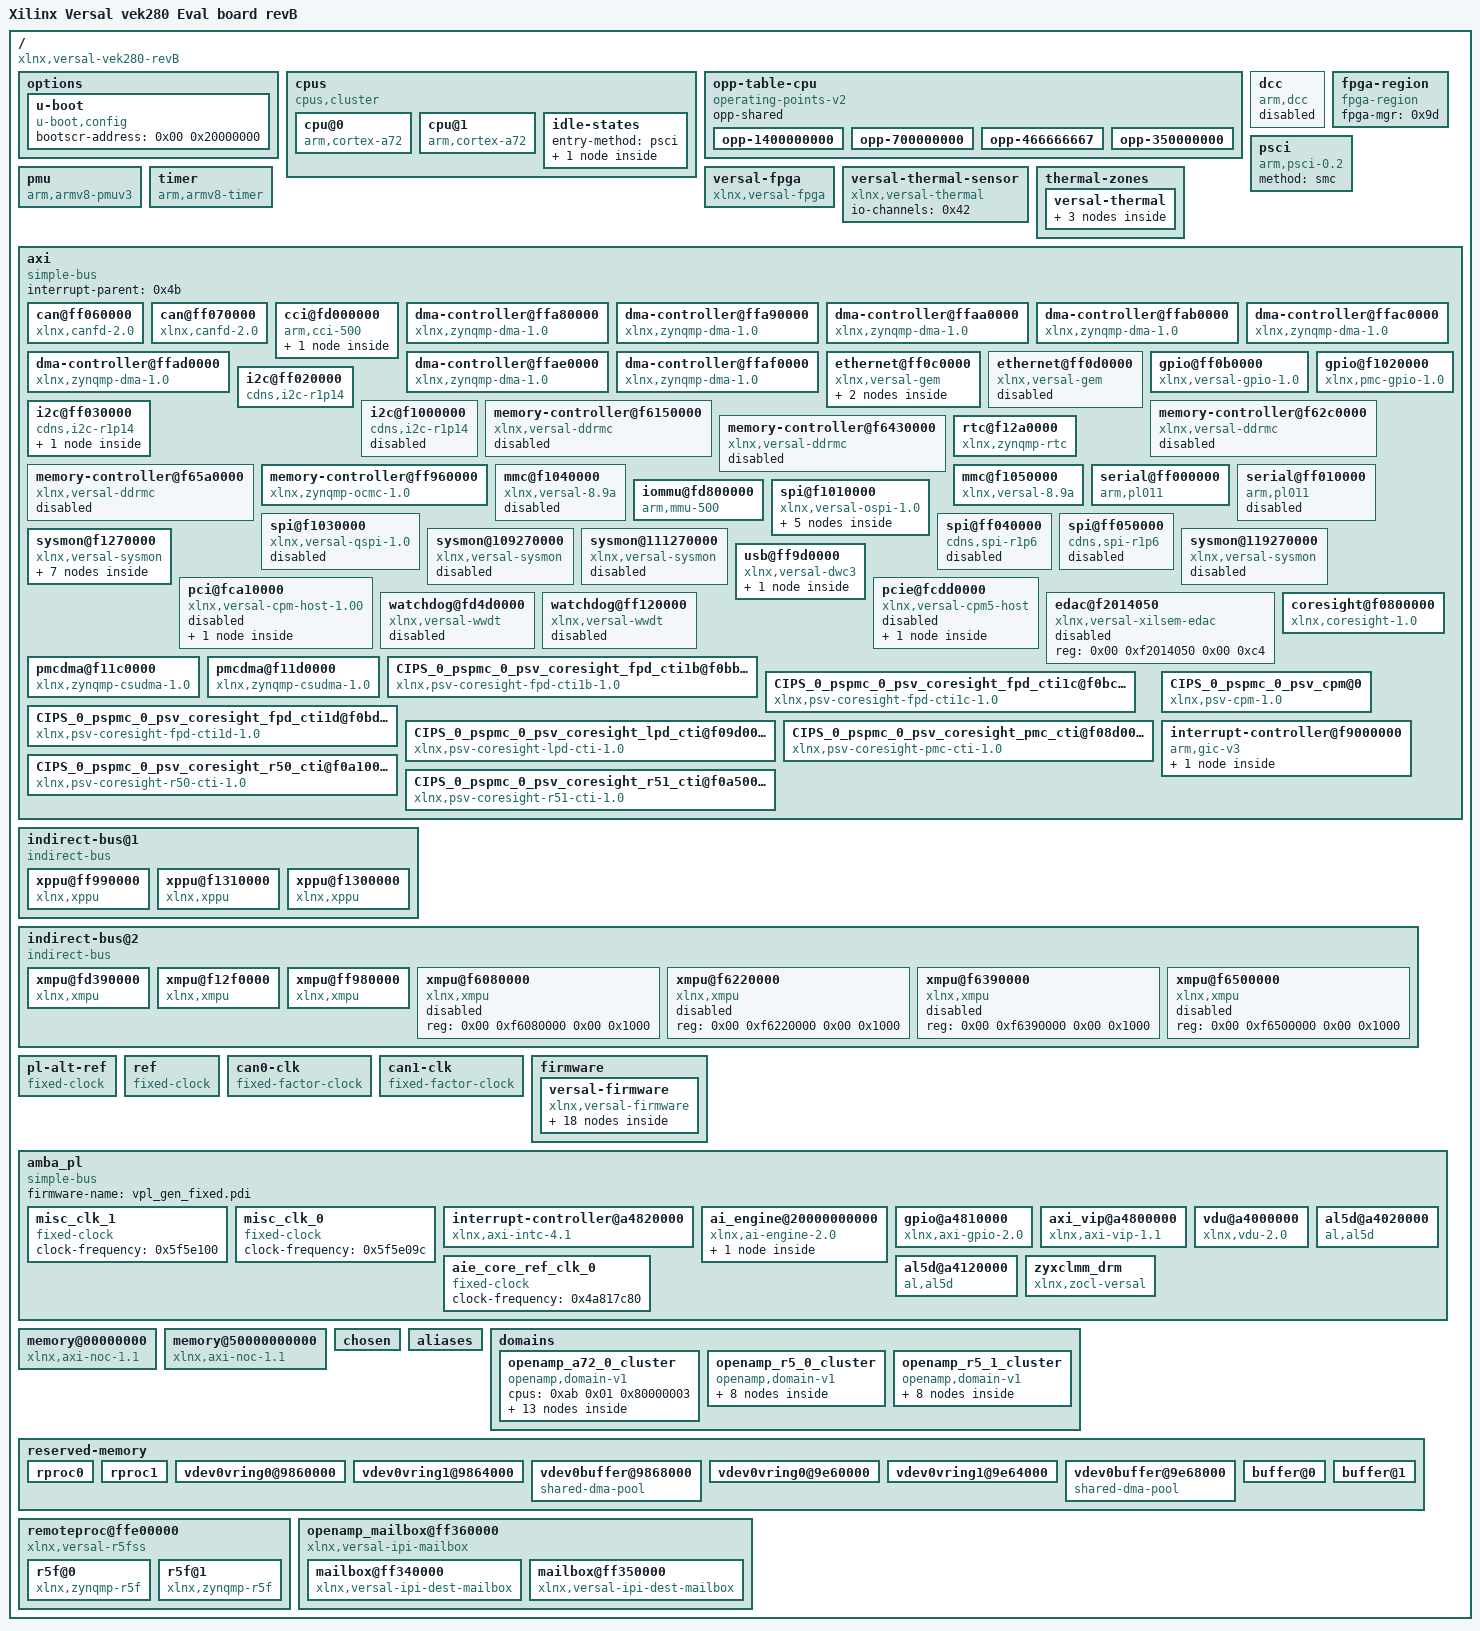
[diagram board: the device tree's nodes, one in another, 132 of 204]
/dts-v1/;

/ {
	compatible = "xlnx,versal-vek280-revB\0xlnx,versal-vek280\0xlnx,versal\0Xilinx Versal vek280 Eval board revB\0Xilinx Versal vek280 Eval board revB\0Xilinx Versal vek280 Eval board revB\0Xilinx Versal vek280 Eval board revB\0Xilinx Versal vek280 Eval board revB\0Xilinx Versal vek280 Eval board revB\0Xilinx Versal vek280 Eval board revB\0Xilinx Versal vek280 Eval board revB\0Xilinx Versal vek280 Eval board revB";
	#address-cells = <0x02>;
	#size-cells = <0x02>;
	model = "Xilinx Versal vek280 Eval board revB";
	board = "vek280";
	device_id = "xcve2802";
	slrcount = <0x01>;
	family = "Versal";
	speed_grade = "2MP";

	options {

		u-boot {
			compatible = "u-boot,config";
			bootscr-address = <0x00 0x20000000>;
		};
	};

	cpus {
		#address-cells = <0x01>;
		#size-cells = <0x00>;
		compatible = "cpus,cluster";
		#ranges-address-cells = <0x02>;
		#ranges-size-cells = <0x02>;
		phandle = <0xab>;

		cpu@0 {
			compatible = "arm,cortex-a72\0arm,armv8";
			device_type = "cpu";
			enable-method = "psci";
			operating-points-v2 = <0x7f>;
			reg = <0x00>;
			cpu-idle-states = <0x80>;
			power-domains = <0x81 0x18110003>;
			clocks = <0x82 0x4d>;
			xlnx,timestamp-clk-freq = <0x5f5e0a4>;
			xlnx,pss-ref-clk-freq = <0x1fca034>;
			stamp-frequency = <0x5f5e0a4>;
			xlnx,ip-name = "psv_cortexa72";
			xlnx,cpu-clk-freq-hz = <0x537248c1>;
			cpu-frequency = <0x537248c1>;
			bus-handle = <0x01>;
			phandle = <0xac>;
		};

		cpu@1 {
			compatible = "arm,cortex-a72\0arm,armv8";
			device_type = "cpu";
			enable-method = "psci";
			operating-points-v2 = <0x7f>;
			reg = <0x01>;
			cpu-idle-states = <0x80>;
			power-domains = <0x81 0x18110004>;
			xlnx,timestamp-clk-freq = <0x5f5e0a4>;
			xlnx,pss-ref-clk-freq = <0x1fca034>;
			stamp-frequency = <0x5f5e0a4>;
			xlnx,ip-name = "psv_cortexa72";
			xlnx,cpu-clk-freq-hz = <0x537248c1>;
			cpu-frequency = <0x537248c1>;
			bus-handle = <0x01>;
			phandle = <0xad>;
		};

		idle-states {
			entry-method = "psci";

			cpu-sleep-0 {
				compatible = "arm,idle-state";
				arm,psci-suspend-param = <0x40000000>;
				local-timer-stop;
				entry-latency-us = <0x12c>;
				exit-latency-us = <0x258>;
				min-residency-us = <0x2710>;
				phandle = <0x80>;
			};
		};
	};

	opp-table-cpu {
		compatible = "operating-points-v2";
		opp-shared;
		phandle = <0x7f>;

		opp-1400000000 {
			opp-hz = <0x00 0x53724e00>;
			clock-latency-ns = <0x7a120>;
			opp-microvolt = <0xf4240>;
		};

		opp-700000000 {
			opp-hz = <0x00 0x29b92700>;
			clock-latency-ns = <0x7a120>;
			opp-microvolt = <0xf4240>;
		};

		opp-466666667 {
			opp-hz = <0x00 0x1bd0c4ab>;
			clock-latency-ns = <0x7a120>;
			opp-microvolt = <0xf4240>;
		};

		opp-350000000 {
			opp-hz = <0x00 0x14dc9380>;
			clock-latency-ns = <0x7a120>;
			opp-microvolt = <0xf4240>;
		};
	};

	dcc {
		compatible = "arm,dcc";
		status = "disabled";
		bootph-all;
		phandle = <0xb6>;
	};

	fpga-region {
		compatible = "fpga-region";
		fpga-mgr = <0x9d>;
		#address-cells = <0x02>;
		#size-cells = <0x02>;
		phandle = <0xb7>;
	};

	psci {
		compatible = "arm,psci-0.2";
		method = "smc";
		phandle = <0xb8>;
	};

	pmu {
		compatible = "arm,armv8-pmuv3";
		interrupt-parent = <0x4b>;
		interrupts = <0x01 0x07 0x304>;
	};

	timer {
		compatible = "arm,armv8-timer";
		interrupt-parent = <0x4b>;
		interrupts = <0x01 0x0d 0x04 0x01 0x0e 0x04 0x01 0x0b 0x04 0x01 0x0a 0x04>;
		phandle = <0xb9>;
	};

	versal-fpga {
		compatible = "xlnx,versal-fpga";
		phandle = <0x9d>;
	};

	versal-thermal-sensor {
		compatible = "xlnx,versal-thermal";
		#thermal-sensor-cells = <0x00>;
		io-channels = <0x42>;
		io-channel-names = "sysmon-temp-channel";
		phandle = <0x9f>;
	};

	thermal-zones {

		versal-thermal {
			polling-delay-passive = <0xfa>;
			polling-delay = <0x3e8>;
			thermal-sensors = <0x9f>;
			phandle = <0xba>;

			trips {

				temp-alert {
					temperature = <0x11170>;
					hysteresis = <0x00>;
					type = "passive";
					phandle = <0xbb>;
				};

				ot-crit {
					temperature = <0x1e848>;
					hysteresis = <0x00>;
					type = "critical";
					phandle = <0xbc>;
				};
			};
		};
	};

	axi {
		compatible = "simple-bus";
		#address-cells = <0x02>;
		#size-cells = <0x02>;
		ranges;
		interrupt-parent = <0x4b>;
		bootph-all;
		phandle = <0x01>;

		can@ff060000 {
			compatible = "xlnx,canfd-2.0";
			status = "okay";
			reg = <0x00 0xff060000 0x00 0x6000>;
			interrupts = <0x00 0x14 0x04>;
			interrupt-parent = <0x4b>;
			clock-names = "can_clk\0s_axi_aclk";
			rx-fifo-depth = <0x40>;
			tx-mailbox-count = <0x20>;
			clocks = <0xa0 0x82 0x52>;
			power-domains = <0x81 0x1822401f>;
			xlnx,can-rx-dpth = <0x40>;
			xlnx,num-of-rx-mb-buf = <0x30>;
			xlnx,can-clk-freq-hz = <0x9896767>;
			xlnx,ip-name = "psv_canfd";
			xlnx,rx-mode = <0x00>;
			xlnx,can-tx-dpth = <0x20>;
			xlnx,num-of-tx-buf = <0x20>;
			xlnx,can-board-interface = "custom";
			phandle = <0x5d>;
		};

		can@ff070000 {
			compatible = "xlnx,canfd-2.0";
			status = "okay";
			reg = <0x00 0xff070000 0x00 0x6000>;
			interrupts = <0x00 0x15 0x04>;
			interrupt-parent = <0x4b>;
			clock-names = "can_clk\0s_axi_aclk";
			rx-fifo-depth = <0x40>;
			tx-mailbox-count = <0x20>;
			clocks = <0xa1 0x82 0x52>;
			power-domains = <0x81 0x18224020>;
			xlnx,can-rx-dpth = <0x40>;
			xlnx,num-of-rx-mb-buf = <0x30>;
			xlnx,can-clk-freq-hz = <0x9896767>;
			xlnx,ip-name = "psv_canfd";
			xlnx,rx-mode = <0x00>;
			xlnx,can-tx-dpth = <0x20>;
			xlnx,num-of-tx-buf = <0x20>;
			xlnx,can-board-interface = "custom";
			phandle = <0x5e>;
		};

		cci@fd000000 {
			compatible = "arm,cci-500";
			status = "okay";
			reg = <0x00 0xfd000000 0x00 0x10000>;
			ranges = <0x00 0x00 0xfd000000 0xa0000>;
			#address-cells = <0x01>;
			#size-cells = <0x01>;
			xlnx,ip-name = "psv_fpd_maincci";
			phandle = <0x4d>;

			pmu@10000 {
				compatible = "arm,cci-500-pmu,r0";
				reg = <0x10000 0x90000>;
				interrupt-parent = <0x4b>;
				interrupts = <0x00 0x6a 0x04 0x00 0x6a 0x04 0x00 0x6a 0x04 0x00 0x6a 0x04 0x00 0x6a 0x04 0x00 0x6a 0x04 0x00 0x6a 0x04 0x00 0x6a 0x04>;
				phandle = <0xbd>;
			};
		};

		dma-controller@ffa80000 {
			compatible = "xlnx,zynqmp-dma-1.0";
			status = "okay";
			reg = <0x00 0xffa80000 0x00 0x1000>;
			interrupts = <0x00 0x3c 0x04>;
			interrupt-parent = <0x4b>;
			clock-names = "clk_main\0clk_apb";
			xlnx,dma-type = <0x01>;
			#dma-cells = <0x01>;
			xlnx,bus-width = <0x40>;
			clocks = <0x82 0x51 0x82 0x52>;
			power-domains = <0x81 0x18224035>;
			xlnx,is-cache-coherent = <0x00>;
			xlnx,ip-name = "psv_adma";
			xlnx,dma-mode = <0x01>;
			phandle = <0x72>;
		};

		dma-controller@ffa90000 {
			compatible = "xlnx,zynqmp-dma-1.0";
			status = "okay";
			reg = <0x00 0xffa90000 0x00 0x1000>;
			interrupts = <0x00 0x3d 0x04>;
			interrupt-parent = <0x4b>;
			clock-names = "clk_main\0clk_apb";
			xlnx,dma-type = <0x01>;
			#dma-cells = <0x01>;
			xlnx,bus-width = <0x40>;
			clocks = <0x82 0x51 0x82 0x52>;
			power-domains = <0x81 0x18224036>;
			xlnx,is-cache-coherent = <0x00>;
			xlnx,ip-name = "psv_adma";
			xlnx,dma-mode = <0x01>;
			phandle = <0x73>;
		};

		dma-controller@ffaa0000 {
			compatible = "xlnx,zynqmp-dma-1.0";
			status = "okay";
			reg = <0x00 0xffaa0000 0x00 0x1000>;
			interrupts = <0x00 0x3e 0x04>;
			interrupt-parent = <0x4b>;
			clock-names = "clk_main\0clk_apb";
			xlnx,dma-type = <0x01>;
			#dma-cells = <0x01>;
			xlnx,bus-width = <0x40>;
			clocks = <0x82 0x51 0x82 0x52>;
			power-domains = <0x81 0x18224037>;
			xlnx,is-cache-coherent = <0x00>;
			xlnx,ip-name = "psv_adma";
			xlnx,dma-mode = <0x01>;
			phandle = <0x74>;
		};

		dma-controller@ffab0000 {
			compatible = "xlnx,zynqmp-dma-1.0";
			status = "okay";
			reg = <0x00 0xffab0000 0x00 0x1000>;
			interrupts = <0x00 0x3f 0x04>;
			interrupt-parent = <0x4b>;
			clock-names = "clk_main\0clk_apb";
			xlnx,dma-type = <0x01>;
			#dma-cells = <0x01>;
			xlnx,bus-width = <0x40>;
			clocks = <0x82 0x51 0x82 0x52>;
			power-domains = <0x81 0x18224038>;
			xlnx,is-cache-coherent = <0x00>;
			xlnx,ip-name = "psv_adma";
			xlnx,dma-mode = <0x01>;
			phandle = <0x75>;
		};

		dma-controller@ffac0000 {
			compatible = "xlnx,zynqmp-dma-1.0";
			status = "okay";
			reg = <0x00 0xffac0000 0x00 0x1000>;
			interrupts = <0x00 0x40 0x04>;
			interrupt-parent = <0x4b>;
			clock-names = "clk_main\0clk_apb";
			xlnx,dma-type = <0x01>;
			#dma-cells = <0x01>;
			xlnx,bus-width = <0x40>;
			clocks = <0x82 0x51 0x82 0x52>;
			power-domains = <0x81 0x18224039>;
			xlnx,is-cache-coherent = <0x00>;
			xlnx,ip-name = "psv_adma";
			xlnx,dma-mode = <0x01>;
			phandle = <0x76>;
		};

		dma-controller@ffad0000 {
			compatible = "xlnx,zynqmp-dma-1.0";
			status = "okay";
			reg = <0x00 0xffad0000 0x00 0x1000>;
			interrupts = <0x00 0x41 0x04>;
			interrupt-parent = <0x4b>;
			clock-names = "clk_main\0clk_apb";
			xlnx,dma-type = <0x01>;
			#dma-cells = <0x01>;
			xlnx,bus-width = <0x40>;
			clocks = <0x82 0x51 0x82 0x52>;
			power-domains = <0x81 0x1822403a>;
			xlnx,is-cache-coherent = <0x00>;
			xlnx,ip-name = "psv_adma";
			xlnx,dma-mode = <0x01>;
			phandle = <0x77>;
		};

		dma-controller@ffae0000 {
			compatible = "xlnx,zynqmp-dma-1.0";
			status = "okay";
			reg = <0x00 0xffae0000 0x00 0x1000>;
			interrupts = <0x00 0x42 0x04>;
			interrupt-parent = <0x4b>;
			clock-names = "clk_main\0clk_apb";
			xlnx,dma-type = <0x01>;
			#dma-cells = <0x01>;
			xlnx,bus-width = <0x40>;
			clocks = <0x82 0x51 0x82 0x52>;
			power-domains = <0x81 0x1822403b>;
			xlnx,is-cache-coherent = <0x00>;
			xlnx,ip-name = "psv_adma";
			xlnx,dma-mode = <0x01>;
			phandle = <0x78>;
		};

		dma-controller@ffaf0000 {
			compatible = "xlnx,zynqmp-dma-1.0";
			status = "okay";
			reg = <0x00 0xffaf0000 0x00 0x1000>;
			interrupts = <0x00 0x43 0x04>;
			interrupt-parent = <0x4b>;
			clock-names = "clk_main\0clk_apb";
			xlnx,dma-type = <0x01>;
			#dma-cells = <0x01>;
			xlnx,bus-width = <0x40>;
			clocks = <0x82 0x51 0x82 0x52>;
			power-domains = <0x81 0x1822403c>;
			xlnx,is-cache-coherent = <0x00>;
			xlnx,ip-name = "psv_adma";
			xlnx,dma-mode = <0x01>;
			phandle = <0x79>;
		};

		ethernet@ff0c0000 {
			compatible = "xlnx,versal-gem\0cdns,gem";
			status = "okay";
			reg = <0x00 0xff0c0000 0x00 0x1000>;
			interrupts = <0x00 0x38 0x04 0x00 0x38 0x04>;
			interrupt-parent = <0x4b>;
			clock-names = "pclk\0hclk\0tx_clk\0rx_clk\0tsu_clk";
			#address-cells = <0x01>;
			#size-cells = <0x00>;
			clocks = <0x82 0x52 0x82 0x58 0x82 0x31 0x82 0x30 0x82 0x2b>;
			power-domains = <0x81 0x18224019>;
			xlnx,has-mdio = <0x01>;
			xlnx,is-cache-coherent = <0x00>;
			xlnx,gem-board-interface = "custom";
			phy-mode = "rgmii-id";
			xlnx,enet-slcr-1000mbps-div0 = <0x02>;
			xlnx,enet-slcr-10mbps-div0 = <0x64>;
			xlnx,enet-tsu-clk-freq-hz = <0xee6b18c>;
			xlnx,ip-name = "psv_ethernet";
			xlnx,eth-mode = <0x01>;
			xlnx,enet-clk-freq-hz = <0x77358c6>;
			xlnx,enet-slcr-100mbps-div0 = <0x0a>;
			phy-handle = <0xa2>;
			phandle = <0x62>;

			mdio {
				#address-cells = <0x01>;
				#size-cells = <0x00>;
				phandle = <0xbe>;

				ethernet-phy@1 {
					#phy-cells = <0x01>;
					compatible = "ethernet-phy-id0283.bc30";
					reg = <0x01>;
					adi,rx-internal-delay-ps = <0x7d0>;
					adi,tx-internal-delay-ps = <0x7d0>;
					adi,fifo-depth-bits = <0x08>;
					reset-gpios = <0x34 0x30 0x01>;
					reset-assert-us = <0x0a>;
					reset-deassert-us = <0x1388>;
					phandle = <0xa2>;
				};
			};
		};

		ethernet@ff0d0000 {
			compatible = "xlnx,versal-gem\0cdns,gem";
			status = "disabled";
			reg = <0x00 0xff0d0000 0x00 0x1000>;
			interrupts = <0x00 0x3a 0x04 0x00 0x3a 0x04>;
			interrupt-parent = <0x4b>;
			clock-names = "pclk\0hclk\0tx_clk\0rx_clk\0tsu_clk";
			#address-cells = <0x01>;
			#size-cells = <0x00>;
			clocks = <0x82 0x52 0x82 0x59 0x82 0x33 0x82 0x32 0x82 0x2b>;
			power-domains = <0x81 0x1822401a>;
			phandle = <0xbf>;
		};

		gpio@ff0b0000 {
			compatible = "xlnx,versal-gpio-1.0";
			status = "okay";
			reg = <0x00 0xff0b0000 0x00 0x1000>;
			interrupts = <0x00 0x0d 0x04>;
			interrupt-parent = <0x4b>;
			#gpio-cells = <0x02>;
			gpio-controller;
			#interrupt-cells = <0x02>;
			interrupt-controller;
			clocks = <0x82 0x52>;
			power-domains = <0x81 0x18224023>;
			xlnx,ip-name = "psv_gpio";
			emio-gpio-width = [00];
			phandle = <0x61>;
		};

		gpio@f1020000 {
			compatible = "xlnx,pmc-gpio-1.0";
			status = "okay";
			reg = <0x00 0xf1020000 0x00 0x1000>;
			interrupts = <0x00 0x7a 0x04>;
			interrupt-parent = <0x4b>;
			#gpio-cells = <0x02>;
			gpio-controller;
			#interrupt-cells = <0x02>;
			interrupt-controller;
			clocks = <0x82 0x3d>;
			power-domains = <0x81 0x1822402c>;
			xlnx,ip-name = "psv_pmc_gpio";
			phandle = <0x34>;
		};

		i2c@ff020000 {
			compatible = "cdns,i2c-r1p14";
			status = "okay";
			reg = <0x00 0xff020000 0x00 0x1000>;
			interrupts = <0x00 0x0e 0x04>;
			interrupt-parent = <0x4b>;
			clock-frequency = <0x186a0>;
			#address-cells = <0x01>;
			#size-cells = <0x00>;
			clocks = <0x82 0x62>;
			power-domains = <0x81 0x1822401d>;
			xlnx,clock-freq = <0x5f5e0a4>;
			xlnx,i2c-clk-freq-hz = <0x5f5e0a4>;
			xlnx,ip-name = "psv_i2c";
			xlnx,iic-board-interface = "custom";
			phandle = <0x5b>;
		};

		i2c@ff030000 {
			compatible = "cdns,i2c-r1p14";
			status = "okay";
			reg = <0x00 0xff030000 0x00 0x1000>;
			interrupts = <0x00 0x0f 0x04>;
			interrupt-parent = <0x4b>;
			clock-frequency = <0x186a0>;
			#address-cells = <0x01>;
			#size-cells = <0x00>;
			clocks = <0x82 0x63>;
			power-domains = <0x81 0x1822401e>;
			xlnx,clock-freq = <0x5f5e0a4>;
			xlnx,i2c-clk-freq-hz = <0x5f5e0a4>;
			xlnx,ip-name = "psv_i2c";
			xlnx,iic-board-interface = "custom";
			bootph-all;
			phandle = <0x5c>;

			eeprom@54 {
				compatible = "st,24c128\0atmel,24c128";
				reg = <0x54>;
				bootph-all;
				phandle = <0xc0>;
			};
		};

		i2c@f1000000 {
			compatible = "cdns,i2c-r1p14";
			status = "disabled";
			reg = <0x00 0xf1000000 0x00 0x1000>;
			interrupts = <0x00 0x7b 0x04>;
			interrupt-parent = <0x4b>;
			clock-frequency = <0x186a0>;
			#address-cells = <0x01>;
			#size-cells = <0x00>;
			clocks = <0x82 0x3e>;
			power-domains = <0x81 0x1822402d>;
			phandle = <0xc1>;
		};

		memory-controller@f6150000 {
			compatible = "xlnx,versal-ddrmc";
			status = "disabled";
			reg = <0x00 0xf6150000 0x00 0x2000 0x00 0xf6070000 0x00 0x20000>;
			reg-names = "base\0noc";
			interrupts = <0x00 0x93 0x04>;
			interrupt-parent = <0x4b>;
			phandle = <0xc2>;
		};

		memory-controller@f62c0000 {
			compatible = "xlnx,versal-ddrmc";
			status = "disabled";
			reg = <0x00 0xf62c0000 0x00 0x2000 0x00 0xf6210000 0x00 0x20000>;
			reg-names = "base\0noc";
			interrupts = <0x00 0x93 0x04>;
			interrupt-parent = <0x4b>;
			phandle = <0xc3>;
		};

		memory-controller@f6430000 {
			compatible = "xlnx,versal-ddrmc";
			status = "disabled";
			reg = <0x00 0xf6430000 0x00 0x2000 0x00 0xf6380000 0x00 0x20000>;
			reg-names = "base\0noc";
			interrupts = <0x00 0x93 0x04>;
			interrupt-parent = <0x4b>;
			phandle = <0xc4>;
		};

		memory-controller@f65a0000 {
			compatible = "xlnx,versal-ddrmc";
			status = "disabled";
			reg = <0x00 0xf65a0000 0x00 0x2000 0x00 0xf64f0000 0x00 0x20000>;
			reg-names = "base\0noc";
			interrupts = <0x00 0x93 0x04>;
			interrupt-parent = <0x4b>;
			phandle = <0xc5>;
		};

		memory-controller@ff960000 {
			compatible = "xlnx,zynqmp-ocmc-1.0";
			reg = <0x00 0xff960000 0x00 0x1000>;
			interrupts = <0x00 0x0a 0x04>;
			interrupt-parent = <0x4b>;
			phandle = <0xc6>;
		};

		rtc@f12a0000 {
			compatible = "xlnx,zynqmp-rtc";
			status = "okay";
			reg = <0x00 0xf12a0000 0x00 0x100>;
			interrupt-names = "alarm\0sec";
			interrupts = <0x00 0x8e 0x04 0x00 0x8f 0x04>;
			interrupt-parent = <0x4b>;
			calibration = <0x7fff>;
			power-domains = <0x81 0x18224034>;
			xlnx,ip-name = "psv_pmc_rtc";
			phandle = <0x43>;
		};

		mmc@f1040000 {
			compatible = "xlnx,versal-8.9a\0arasan,sdhci-8.9a";
			status = "disabled";
			reg = <0x00 0xf1040000 0x00 0x10000>;
			interrupts = <0x00 0x7e 0x04>;
			interrupt-parent = <0x4b>;
			clock-names = "clk_xin\0clk_ahb\0gate";
			#clock-cells = <0x01>;
			clock-output-names = "clk_out_sd0\0clk_in_sd0";
			clocks = <0x82 0x3b 0x82 0x52 0x82 0x4a>;
			power-domains = <0x81 0x1822402e>;
			phandle = <0xc7>;
		};

		mmc@f1050000 {
			compatible = "xlnx,versal-8.9a\0arasan,sdhci-8.9a";
			status = "okay";
			reg = <0x00 0xf1050000 0x00 0x10000>;
			interrupts = <0x00 0x80 0x04>;
			interrupt-parent = <0x4b>;
			clock-names = "clk_xin\0clk_ahb\0gate";
			#clock-cells = <0x01>;
			clock-output-names = "clk_out_sd1\0clk_in_sd1";
			clocks = <0x82 0x3c 0x82 0x52 0x82 0x4a>;
			power-domains = <0x81 0x1822402f>;
			xlnx,sd-board-interface = "custom";
			xlnx,is-cache-coherent = <0x00>;
			xlnx,clk-50-ddr-otap-dly = <0x03>;
			xlnx,clk-50-sdr-itap-dly = <0x2c>;
			xlnx,has-emio = <0x00>;
			clock-frequency = <0xbebc149>;
			xlnx,clk-100-sdr-otap-dly = <0x03>;
			xlnx,mio-bank = <0x01>;
			xlnx,ip-name = "psv_pmc_sd";
			xlnx,bus-width = <0x08>;
			xlnx,card-detect = <0x01>;
			xlnx,has-wp = <0x00>;
			xlnx,has-cd = <0x01>;
			xlnx,slot-type = <0x03>;
			xlnx,clk-50-sdr-otap-dly = <0x04>;
			xlnx,clk-50-ddr-itap-dly = <0x36>;
			xlnx,has-power = <0x01>;
			xlnx,clk-200-sdr-otap-dly = <0x02>;
			xlnx,sdio-clk-freq-hz = <0xbebc149>;
			xlnx,write-protect = <0x00>;
			no-1-8-v;
			phandle = <0x35>;
		};

		serial@ff000000 {
			compatible = "arm,pl011\0arm,primecell";
			status = "okay";
			reg = <0x00 0xff000000 0x00 0x1000>;
			interrupts = <0x00 0x12 0x04>;
			interrupt-parent = <0x4b>;
			reg-io-width = <0x04>;
			clock-names = "uartclk\0apb_pclk";
			bootph-all;
			clocks = <0x82 0x5c 0x82 0x52>;
			power-domains = <0x81 0x18224021>;
			xlnx,clock-freq = <0x5f5e0a4>;
			u-boot,dm-pre-reloc;
			xlnx,uart-board-interface = "custom";
			xlnx,has-modem = <0x00>;
			xlnx,ip-name = "psv_sbsauart";
			xlnx,baudrate = <0x1c200>;
			cts-override;
			port-number = <0x00>;
			xlnx,uart-clk-freq-hz = <0x5f5e0a4>;
			phandle = <0x5a>;
		};

		serial@ff010000 {
			compatible = "arm,pl011\0arm,primecell";
			status = "disabled";
			reg = <0x00 0xff010000 0x00 0x1000>;
			interrupts = <0x00 0x13 0x04>;
			interrupt-parent = <0x4b>;
			reg-io-width = <0x04>;
			clock-names = "uartclk\0apb_pclk";
			bootph-all;
			clocks = <0x82 0x5d 0x82 0x52>;
			power-domains = <0x81 0x18224022>;
			phandle = <0xc8>;
		};

		iommu@fd800000 {
			compatible = "arm,mmu-500";
			status = "okay";
			reg = <0x00 0xfd800000 0x00 0x40000>;
			stream-match-mask = <0x7c00>;
			#iommu-cells = <0x01>;
			#global-interrupts = <0x01>;
			interrupts = <0x00 0x6b 0x04 0x00 0x6b 0x04 0x00 0x6b 0x04 0x00 0x6b 0x04 0x00 0x6b 0x04 0x00 0x6b 0x04 0x00 0x6b 0x04 0x00 0x6b 0x04 0x00 0x6b 0x04 0x00 0x6b 0x04 0x00 0x6b 0x04 0x00 0x6b 0x04 0x00 0x6b 0x04 0x00 0x6b 0x04 0x00 0x6b 0x04 0x00 0x6b 0x04 0x00 0x6b 0x04 0x00 0x6b 0x04 0x00 0x6b 0x04 0x00 0x6b 0x04 0x00 0x6b 0x04 0x00 0x6b 0x04 0x00 0x6b 0x04 0x00 0x6b 0x04 0x00 0x6b 0x04 0x00 0x6b 0x04 0x00 0x6b 0x04 0x00 0x6b 0x04 0x00 0x6b 0x04 0x00 0x6b 0x04 0x00 0x6b 0x04 0x00 0x6b 0x04 0x00 0x6b 0x04>;
			interrupt-parent = <0x4b>;
			xlnx,ip-name = "psv_fpd_smmutcu";
			phandle = <0x58>;
		};

		spi@f1010000 {
			compatible = "xlnx,versal-ospi-1.0\0cdns,qspi-nor";
			status = "okay";
			reg = <0x00 0xf1010000 0x00 0x10000 0x00 0xc0000000 0x00 0x20000000>;
			interrupts = <0x00 0x7c 0x04>;
			interrupt-parent = <0x4b>;
			cdns,fifo-depth = <0x100>;
			cdns,fifo-width = <0x04>;
			cdns,is-dma = <0x01>;
			cdns,trigger-address = <0xc0000000>;
			#address-cells = <0x01>;
			#size-cells = <0x00>;
			clocks = <0x82 0x3a>;
			power-domains = <0x81 0x1822402a>;
			reset-names = "qspi";
			resets = <0xa3 0xc10402e>;
			is-stacked = <0x00>;
			xlnx,is-cache-coherent = <0x00>;
			xlnx,clock-freq = <0xbebc149>;
			xlnx,ip-name = "psv_pmc_ospi";
			xlnx,ospi-clk-freq-hz = <0xbebc149>;
			is-dual = <0x00>;
			xlnx,ospi-mode = <0x00>;
			bus-num = <0x02>;
			num-cs = <0x01>;
			#stream-id-cells = <0x01>;
			phandle = <0x33>;

			flash@0 {
				compatible = "mt35xu02g\0micron,m25p80\0jedec,spi-nor";
				reg = <0x00>;
				#address-cells = <0x01>;
				#size-cells = <0x01>;
				cdns,read-delay = <0x00>;
				cdns,tshsl-ns = <0x00>;
				cdns,tsd2d-ns = <0x00>;
				cdns,tchsh-ns = <0x01>;
				cdns,tslch-ns = <0x01>;
				spi-tx-bus-width = <0x08>;
				spi-rx-bus-width = <0x08>;
				spi-max-frequency = <0x1312d00>;
				no-wp;
				reset-gpios = <0x34 0x0c 0x01>;
				phandle = <0x02>;

				partition@0 {
					label = "spi0-boot";
					reg = <0x00 0x40000>;
				};

				partition@1 {
					label = "spi0-bootenv";
					reg = <0x40000 0x20000>;
				};

				partition@2 {
					label = "spi0-config";
					reg = <0x60000 0x20000>;
				};

				partition@3 {
					label = "spi0-kernel";
					reg = <0x80000 0xc00000>;
				};
			};
		};

		spi@f1030000 {
			compatible = "xlnx,versal-qspi-1.0";
			status = "disabled";
			reg = <0x00 0xf1030000 0x00 0x1000>;
			interrupts = <0x00 0x7d 0x04>;
			interrupt-parent = <0x4b>;
			clock-names = "ref_clk\0pclk";
			#address-cells = <0x01>;
			#size-cells = <0x00>;
			clocks = <0x82 0x39 0x82 0x52>;
			power-domains = <0x81 0x1822402b>;
			phandle = <0xc9>;
		};

		spi@ff040000 {
			compatible = "cdns,spi-r1p6";
			status = "disabled";
			reg = <0x00 0xff040000 0x00 0x1000>;
			interrupts = <0x00 0x10 0x04>;
			interrupt-parent = <0x4b>;
			clock-names = "ref_clk\0pclk";
			#address-cells = <0x01>;
			#size-cells = <0x00>;
			clocks = <0x82 0x5e 0x82 0x52>;
			power-domains = <0x81 0x1822401b>;
			phandle = <0xca>;
		};

		spi@ff050000 {
			compatible = "cdns,spi-r1p6";
			status = "disabled";
			reg = <0x00 0xff050000 0x00 0x1000>;
			interrupts = <0x00 0x11 0x04>;
			interrupt-parent = <0x4b>;
			clock-names = "ref_clk\0pclk";
			#address-cells = <0x01>;
			#size-cells = <0x00>;
			clocks = <0x82 0x5f 0x82 0x52>;
			power-domains = <0x81 0x1822401c>;
			phandle = <0xcb>;
		};

		sysmon@f1270000 {
			compatible = "xlnx,versal-sysmon";
			#io-channel-cells = <0x00>;
			reg = <0x00 0xf1270000 0x00 0x4000>;
			interrupts = <0x00 0x90 0x04>;
			xlnx,numchannels = [07];
			#address-cells = <0x02>;
			#size-cells = <0x02>;
			xlnx,nodeid = <0x18224055>;
			xlnx,sat-63-desc = "PS , FPD , satellite";
			xlnx,sat-1-desc = "PMC , system , ADC";
			xlnx,sat-17-x = <0x40b7>;
			xlnx,sat-9-x = <0x315e>;
			xlnx,sat-20-desc = "VNOC , satellite";
			xlnx,sat-19-desc = "Clocking , column , satellite";
			xlnx,sat-17-y = <0x1795>;
			xlnx,sat-9-y = <0x34f8>;
			xlnx,sat-22-x = <0x2624>;
			xlnx,meas-0-root-id = <0x00>;
			xlnx,sat-22-y = <0x25ed>;
			xlnx,meas-1-root-id = <0x05>;
			xlnx,ip-name = "psv_pmc_sysmon";
			xlnx,meas-2-root-id = <0x01>;
			xlnx,sat-16-desc = "Clocking , column , satellite";
			xlnx,meas-2-slr-number = <0x00>;
			xlnx,meas-3-root-id = <0x02>;
			xlnx,sat-9-desc = "ME , satellite";
			xlnx,sat-26-x = <0x18d1>;
			xlnx,meas-4-root-id = <0x03>;
			xlnx,sat-28-desc = "ME , satellite";
			xlnx,sat-26-y = <0x19f9>;
			xlnx,meas-5-root-id = <0x04>;
			xlnx,sat-10-x = <0x2995>;
			xlnx,sat-64-x = <0x23>;
			xlnx,sat-2-x = <0x23>;
			xlnx,meas-6-root-id = <0x06>;
			xlnx,sat-10-y = <0x34f8>;
			xlnx,sat-64-y = <0xb34>;
			xlnx,sat-2-y = <0xb34>;
			xlnx,sat-13-desc = "Clocking , column , satellite";
			xlnx,sat-31-x = <0xa0e>;
			xlnx,sat-6-desc = "VNOC , satellite";
			xlnx,sat-31-y = <0x2ff0>;
			xlnx,sat-14-x = <0x40b7>;
			xlnx,sat-6-x = <0x3377>;
			xlnx,sat-25-desc = "VNOC , satellite";
			xlnx,sat-14-y = <0x29b7>;
			xlnx,sat-6-y = <0xe06>;
			xlnx,sat-10-desc = "ME , satellite";
			xlnx,sat-18-x = <0x40b7>;
			xlnx,sat-3-desc = "XPIO , satellite";
			xlnx,sat-18-y = <0x11d0>;
			xlnx,meas-5-slr-number = <0x00>;
			xlnx,sat-22-desc = "VNOC , satellite";
			xlnx,sat-23-x = <0x21cc>;
			xlnx,meas-0-slr-number = <0x00>;
			xlnx,sat-23-y = <0x34f8>;
			xlnx,sat-18-desc = "Clocking , column , satellite";
			xlnx,sat-27-x = <0x18d1>;
			xlnx,sat-27-y = <0x25ed>;
			xlnx,sat-11-x = <0x3926>;
			xlnx,sat-3-x = <0x116a>;
			xlnx,sat-31-desc = "Clocking , column , satellite";
			xlnx,sat-11-y = <0x34f8>;
			xlnx,sat-3-y = <0x5ff>;
			status = "okay";
			xlnx,sat-15-desc = "Clocking , column , satellite";
			xlnx,sat-15-x = <0x40b7>;
			xlnx,sat-8-desc = "VNOC , satellite";
			xlnx,sat-7-x = <0x3377>;
			xlnx,sat-15-y = <0x2389>;
			xlnx,sat-7-y = <0x19f9>;
			xlnx,sat-27-desc = "VNOC , satellite";
			xlnx,meas-3-slr-number = <0x00>;
			xlnx,sat-20-x = <0x2624>;
			xlnx,sat-19-x = <0x40b7>;
			xlnx,sat-12-desc = "ME , satellite";
			xlnx,sat-20-y = <0xe06>;
			xlnx,sat-19-y = <0xba1>;
			xlnx,sat-5-desc = "XPIO , satellite";
			xlnx,sat-24-desc = "ME , satellite";
			xlnx,sat-24-x = <0x1a03>;
			xlnx,sat-24-y = <0x34f8>;
			xlnx,sat-64-desc = "PS , LPD , satellite";
			xlnx,sat-2-desc = "PMC , user , ADC";
			xlnx,sat-28-x = <0x123a>;
			xlnx,sat-21-desc = "VNOC , satellite";
			xlnx,sat-28-y = <0x34f8>;
			xlnx,meas-6-slr-number = <0x00>;
			xlnx,sat-12-x = <0x40ef>;
			xlnx,sat-4-x = <0x290a>;
			xlnx,sat-12-y = <0x34f8>;
			xlnx,sat-4-y = <0x5ff>;
			xlnx,meas-1-slr-number = <0x00>;
			xlnx,sat-16-x = <0x40b7>;
			xlnx,sat-17-desc = "Clocking , column , satellite";
			xlnx,sat-8-x = <0x3377>;
			xlnx,sat-16-y = <0x1dc4>;
			xlnx,sat-8-y = <0x25ed>;
			xlnx,meas-0 = "VCCAUX";
			xlnx,sat-30-desc = "ME , satellite";
			xlnx,sat-29-desc = "ME , satellite";
			xlnx,meas-1 = "VCC_SOC";
			xlnx,sat-21-x = <0x2624>;
			xlnx,meas-2 = "VCCAUX_PMC";
			xlnx,sat-21-y = <0x19f9>;
			xlnx,meas-3 = "VCC_PMC";
			xlnx,sat-14-desc = "Clocking , column , satellite";
			xlnx,meas-4 = "VCC_PSFP";
			xlnx,sat-7-desc = "VNOC , satellite";
			xlnx,meas-5 = "VCC_PSLP";
			xlnx,sat-26-desc = "VNOC , satellite";
			xlnx,sat-25-x = <0x18d1>;
			xlnx,meas-6 = "VP_VN";
			xlnx,sat-25-y = <0xe06>;
			xlnx,sat-63-x = <0x23>;
			xlnx,sat-1-x = <0x23>;
			xlnx,meas-4-slr-number = <0x00>;
			xlnx,sat-11-desc = "ME , satellite";
			xlnx,sat-63-y = <0xb34>;
			xlnx,sat-1-y = <0xb34>;
			xlnx,sat-4-desc = "XPIO , satellite";
			xlnx,sat-30-x = <0x2a8>;
			xlnx,sat-29-x = <0xa71>;
			xlnx,sat-30-y = <0x34f8>;
			xlnx,sat-29-y = <0x34f8>;
			xlnx,sat-23-desc = "ME , satellite";
			xlnx,sat-13-x = <0x40b7>;
			xlnx,sat-5-x = <0x40aa>;
			xlnx,sat-13-y = <0x2ff0>;
			xlnx,sat-5-y = <0x5ff>;
			phandle = <0x42>;

			supply@0 {
				reg = <0x00>;
				xlnx,name = "vccaux";
			};

			supply@5 {
				reg = <0x05>;
				xlnx,name = "vcc_soc";
			};

			supply@1 {
				reg = <0x01>;
				xlnx,name = "vccaux_pmc";
			};

			supply@2 {
				reg = <0x02>;
				xlnx,name = "vcc_pmc";
			};

			supply@3 {
				reg = <0x03>;
				xlnx,name = "vcc_psfp";
			};

			supply@4 {
				reg = <0x04>;
				xlnx,name = "vcc_pslp";
			};

			supply@6 {
				reg = <0x06>;
				xlnx,name = "vp_vn";
			};
		};

		sysmon@109270000 {
			compatible = "xlnx,versal-sysmon";
			status = "disabled";
			reg = <0x01 0x9270000 0x00 0x4000>;
			xlnx,numchannels = [00];
			#address-cells = <0x01>;
			#size-cells = <0x00>;
			xlnx,nodeid = <0x18225055>;
			phandle = <0xcc>;
		};

		sysmon@111270000 {
			compatible = "xlnx,versal-sysmon";
			status = "disabled";
			reg = <0x01 0x11270000 0x00 0x4000>;
			xlnx,numchannels = [00];
			#address-cells = <0x01>;
			#size-cells = <0x00>;
			xlnx,nodeid = <0x18226055>;
			phandle = <0xcd>;
		};

		sysmon@119270000 {
			compatible = "xlnx,versal-sysmon";
			status = "disabled";
			reg = <0x01 0x19270000 0x00 0x4000>;
			xlnx,numchannels = [00];
			#address-cells = <0x01>;
			#size-cells = <0x00>;
			xlnx,nodeid = <0x18227055>;
			phandle = <0xce>;
		};

		usb@ff9d0000 {
			compatible = "xlnx,versal-dwc3";
			status = "okay";
			reg = <0x00 0xff9d0000 0x00 0x100>;
			clock-names = "bus_clk\0ref_clk";
			ranges;
			#address-cells = <0x02>;
			#size-cells = <0x02>;
			clocks = <0x82 0x5b 0x82 0x68>;
			power-domains = <0x81 0x18224018>;
			resets = <0xa3 0xc104036>;
			xlnx,ip-name = "psv_usb";
			phandle = <0x71>;

			usb@fe200000 {
				compatible = "snps,dwc3";
				status = "okay";
				reg = <0x00 0xfe200000 0x00 0x10000>;
				interrupt-names = "host\0peripheral\0otg\0wakeup";
				interrupts = <0x00 0x16 0x04 0x00 0x16 0x04 0x00 0x1a 0x04 0x00 0x4a 0x04>;
				interrupt-parent = <0x4b>;
				snps,dis_u2_susphy_quirk;
				snps,dis_u3_susphy_quirk;
				snps,quirk-frame-length-adjustment = <0x20>;
				clock-names = "ref";
				clocks = <0x82 0x5b>;
				xlnx,is-cache-coherent = <0x00>;
				xlnx,ip-name = "psv_usb_xhci";
				xlnx,enable-superspeed = <0x00>;
				dr_mode = "host";
				maximum-speed = "high-speed";
				snps,usb3_lpm_capable;
				phandle = <0x59>;
			};
		};

		pci@fca10000 {
			device_type = "pci";
			#address-cells = <0x03>;
			#interrupt-cells = <0x01>;
			#size-cells = <0x02>;
			compatible = "xlnx,versal-cpm-host-1.00";
			status = "disabled";
			interrupt-map = <0x01 0xa4 0x00 0x02 0xa4 0x01 0x03 0xa4 0x02 0x04 0xa4 0x03>;
			interrupt-map-mask = <0x00 0x00 0x00 0x07>;
			interrupt-names = "misc";
			interrupts = <0x00 0x48 0x04>;
			xlnx,csr-slcr = <0x06 0x00>;
			xlnx,num-of-bars = <0x02>;
			xlnx,port-type = <0x01>;
			interrupt-parent = <0x4b>;
			bus-range = <0x00 0xff>;
			ranges = <0x2000000 0x00 0xe0010000 0x00 0xe0010000 0x00 0x10000000 0x43000000 0x80 0x00 0x80 0x00 0x00 0x80000000>;
			msi-map = <0x00 0x07 0x00 0x10000>;
			reg = <0x06 0x00 0x00 0x1000000 0x00 0xfca10000 0x00 0x1000 0x00 0xfca00000 0x00 0x10000>;
			reg-names = "cfg\0cpm_slcr\0cpm_crx";
			phandle = <0xcf>;

			interrupt-controller {
				#address-cells = <0x00>;
				#interrupt-cells = <0x01>;
				interrupt-controller;
				phandle = <0xa4>;
			};
		};

		pcie@fcdd0000 {
			device_type = "pci";
			#address-cells = <0x03>;
			#interrupt-cells = <0x01>;
			#size-cells = <0x02>;
			compatible = "xlnx,versal-cpm5-host";
			status = "disabled";
			interrupt-map = <0x01 0xa5 0x00 0x02 0xa5 0x01 0x03 0xa5 0x02 0x04 0xa5 0x03>;
			interrupt-map-mask = <0x00 0x00 0x00 0x07>;
			interrupt-names = "misc";
			interrupts = <0x00 0x48 0x04>;
			xlnx,csr-slcr = <0xfce20000>;
			xlnx,num-of-bars = <0x02>;
			xlnx,port-type = <0x01>;
			interrupt-parent = <0x4b>;
			bus-range = <0x00 0xff>;
			ranges = <0x2000000 0x00 0xe0000000 0x00 0xe0000000 0x00 0x10000000 0x43000000 0x80 0x00 0x80 0x00 0x00 0x80000000>;
			msi-map = <0x00 0x07 0x00 0x10000>;
			reg = <0x06 0x00 0x00 0x1000000 0x00 0xfcdd0000 0x00 0x1000 0x00 0xfce20000 0x00 0x10000 0x00 0xfcdc0000 0x00 0x10000>;
			reg-names = "cfg\0cpm_slcr\0cpm_csr\0cpm_crx";
			phandle = <0xd0>;

			interrupt-controller {
				#address-cells = <0x00>;
				#interrupt-cells = <0x01>;
				interrupt-controller;
				phandle = <0xa5>;
			};
		};

		watchdog@fd4d0000 {
			compatible = "xlnx,versal-wwdt";
			status = "disabled";
			reg = <0x00 0xfd4d0000 0x00 0x10000>;
			interrupt-names = "wdt\0wwdt_reset_pending\0gwdt\0gwdt_reset_pending";
			interrupts = <0x00 0x64 0x01 0x00 0x6d 0x01 0x00 0x6c 0x01 0x00 0x6e 0x01>;
			interrupt-parent = <0x4b>;
			timeout-sec = <0x1e>;
			clocks = <0x82 0x4c>;
			power-domains = <0x81 0x18224029>;
			phandle = <0xd1>;
		};

		watchdog@ff120000 {
			compatible = "xlnx,versal-wwdt";
			status = "disabled";
			reg = <0x00 0xff120000 0x00 0x10000>;
			interrupt-parent = <0x4b>;
			interrupt-names = "wdt\0wwdt_reset_pending\0gwdt\0gwdt_reset_pending";
			interrupts = <0x00 0x31 0x01 0x00 0x45 0x01 0x00 0x46 0x04 0x00 0x47 0x04>;
			timeout-sec = <0x1e>;
			clocks = <0x82 0x52>;
			power-domains = <0x81 0x18224028>;
			phandle = <0xd2>;
		};

		edac@f2014050 {
			compatible = "xlnx,versal-xilsem-edac";
			status = "disabled";
			reg = <0x00 0xf2014050 0x00 0xc4>;
			phandle = <0xd3>;
		};

		pmcdma@f11c0000 {
			status = "okay";
			compatible = "xlnx,zynqmp-csudma-1.0";
			interrupt-parent = <0x4b>;
			interrupts = <0x00 0x83 0x04>;
			reg = <0x00 0xf11c0000 0x00 0x10000>;
			xlnx,dma-type = <0x01>;
			xlnx,ip-name = "psv_pmc_dma";
			phandle = <0x37>;
		};

		pmcdma@f11d0000 {
			status = "okay";
			compatible = "xlnx,zynqmp-csudma-1.0";
			interrupt-parent = <0x4b>;
			interrupts = <0x00 0x84 0x04>;
			reg = <0x00 0xf11d0000 0x00 0x10000>;
			xlnx,dma-type = <0x02>;
			xlnx,ip-name = "psv_pmc_dma";
			phandle = <0x38>;
		};

		coresight@f0800000 {
			compatible = "xlnx,coresight-1.0";
			status = "okay";
			reg = <0x00 0xf0800000 0x00 0x10000>;
			xlnx,ip-name = "psv_coresight";
			phandle = <0x13>;
		};

		CIPS_0_pspmc_0_psv_coresight_fpd_cti1b@f0bb0000 {
			compatible = "xlnx,psv-coresight-fpd-cti1b-1.0";
			status = "okay";
			xlnx,ip-name = "psv_coresight_fpd_cti1b";
			reg = <0x00 0xf0bb0000 0x00 0x10000>;
			phandle = <0x1b>;
		};

		CIPS_0_pspmc_0_psv_coresight_fpd_cti1c@f0bc0000 {
			compatible = "xlnx,psv-coresight-fpd-cti1c-1.0";
			status = "okay";
			xlnx,ip-name = "psv_coresight_fpd_cti1c";
			reg = <0x00 0xf0bc0000 0x00 0x10000>;
			phandle = <0x1c>;
		};

		CIPS_0_pspmc_0_psv_coresight_fpd_cti1d@f0bd0000 {
			compatible = "xlnx,psv-coresight-fpd-cti1d-1.0";
			status = "okay";
			xlnx,ip-name = "psv_coresight_fpd_cti1d";
			reg = <0x00 0xf0bd0000 0x00 0x10000>;
			phandle = <0x1d>;
		};

		CIPS_0_pspmc_0_psv_coresight_lpd_cti@f09d0000 {
			compatible = "xlnx,psv-coresight-lpd-cti-1.0";
			status = "okay";
			xlnx,ip-name = "psv_coresight_lpd_cti";
			reg = <0x00 0xf09d0000 0x00 0x10000>;
			phandle = <0x16>;
		};

		CIPS_0_pspmc_0_psv_coresight_pmc_cti@f08d0000 {
			compatible = "xlnx,psv-coresight-pmc-cti-1.0";
			status = "okay";
			xlnx,ip-name = "psv_coresight_pmc_cti";
			reg = <0x00 0xf08d0000 0x00 0x10000>;
			phandle = <0x14>;
		};

		CIPS_0_pspmc_0_psv_coresight_r50_cti@f0a10000 {
			compatible = "xlnx,psv-coresight-r50-cti-1.0";
			status = "okay";
			xlnx,ip-name = "psv_coresight_r50_cti";
			reg = <0x00 0xf0a10000 0x00 0x10000>;
			phandle = <0x17>;
		};

		CIPS_0_pspmc_0_psv_coresight_r51_cti@f0a50000 {
			compatible = "xlnx,psv-coresight-r51-cti-1.0";
			status = "okay";
			xlnx,ip-name = "psv_coresight_r51_cti";
			reg = <0x00 0xf0a50000 0x00 0x10000>;
			phandle = <0x18>;
		};

		CIPS_0_pspmc_0_psv_cpm@0 {
			xlnx,cpm5-slcr-addr = <0xfcdd0000>;
			compatible = "xlnx,psv-cpm-1.0";
			status = "okay";
			xlnx,ip-name = "psv_cpm";
			reg = <0x00 0xfc000000 0x00 0x1000000>;
			xlnx,cpm-slcr = <0xfca10000>;
			xlnx,cpm5-dma0-csr-addr = <0xfce20000>;
			phandle = <0x4c>;
		};

		interrupt-controller@f9000000 {
			phandle = <0x4b>;
			xlnx,ip-name = "psv_acpu_gic";
			xlnx,apu-gic-its-ctl = <0xf9020000>;
			status = "okay";
			interrupts = <0x01 0x09 0x04>;
			interrupt-parent = <0x4b>;
			interrupt-controller;
			reg = <0x00 0xf9000000 0x00 0x80000 0x00 0xf9080000 0x00 0x80000>;
			ranges;
			#size-cells = <0x02>;
			#address-cells = <0x02>;
			#interrupt-cells = <0x03>;
			compatible = "arm,gic-v3";

			msi-controller@f9020000 {
				phandle = <0x07>;
				reg = <0x00 0xf9020000 0x00 0x20000>;
				#msi-cells = <0x01>;
				msi-controller;
				status = "okay";
				compatible = "arm,gic-v3-its";
			};
		};
	};

	indirect-bus@1 {
		compatible = "indirect-bus";
		#address-cells = <0x02>;
		#size-cells = <0x02>;
		phandle = <0x140>;

		xppu@ff990000 {
			compatible = "xlnx,xppu";
			#firewall-cells = <0x00>;
			reg = <0x00 0xff990000 0x00 0x2000>;
			status = "okay";
			xlnx,ip-name = "psv_lpd_xppu";
			phandle = <0x6e>;
		};

		xppu@f1310000 {
			compatible = "xlnx,xppu";
			#firewall-cells = <0x00>;
			reg = <0x00 0xf1310000 0x00 0x2000>;
			status = "okay";
			xlnx,ip-name = "psv_pmc_xppu";
			phandle = <0x48>;
		};

		xppu@f1300000 {
			compatible = "xlnx,xppu";
			#firewall-cells = <0x00>;
			reg = <0x00 0xf1300000 0x00 0x2000>;
			status = "okay";
			xlnx,ip-name = "psv_pmc_xppu_npi";
			phandle = <0x47>;
		};
	};

	indirect-bus@2 {
		compatible = "indirect-bus";
		#address-cells = <0x02>;
		#size-cells = <0x02>;
		phandle = <0x141>;

		xmpu@fd390000 {
			compatible = "xlnx,xmpu";
			#firewall-cells = <0x00>;
			reg = <0x00 0xfd390000 0x00 0x1000>;
			status = "okay";
			xlnx,ip-name = "psv_fpd_slave_xmpu";
			phandle = <0x51>;
		};

		xmpu@f12f0000 {
			compatible = "xlnx,xmpu";
			#firewall-cells = <0x00>;
			reg = <0x00 0xf12f0000 0x00 0x1000>;
			status = "okay";
			xlnx,ip-name = "psv_pmc_xmpu";
			phandle = <0x46>;
		};

		xmpu@ff980000 {
			compatible = "xlnx,xmpu";
			#firewall-cells = <0x00>;
			reg = <0x00 0xff980000 0x00 0x1000>;
			status = "okay";
			xlnx,ip-name = "psv_ocm_xmpu";
			phandle = <0x6d>;
		};

		xmpu@f6080000 {
			compatible = "xlnx,xmpu";
			#firewall-cells = <0x00>;
			reg = <0x00 0xf6080000 0x00 0x1000>;
			status = "disabled";
			phandle = <0x142>;
		};

		xmpu@f6220000 {
			compatible = "xlnx,xmpu";
			#firewall-cells = <0x00>;
			reg = <0x00 0xf6220000 0x00 0x1000>;
			status = "disabled";
			phandle = <0x143>;
		};

		xmpu@f6390000 {
			compatible = "xlnx,xmpu";
			#firewall-cells = <0x00>;
			reg = <0x00 0xf6390000 0x00 0x1000>;
			status = "disabled";
			phandle = <0x144>;
		};

		xmpu@f6500000 {
			compatible = "xlnx,xmpu";
			#firewall-cells = <0x00>;
			reg = <0x00 0xf6500000 0x00 0x1000>;
			status = "disabled";
			phandle = <0x145>;
		};
	};

	pl-alt-ref {
		bootph-all;
		compatible = "fixed-clock";
		#clock-cells = <0x00>;
		clock-frequency = <0x1fca055>;
		clock-output-names = "pl_alt_ref_clk";
		phandle = <0xa7>;
	};

	ref {
		bootph-all;
		compatible = "fixed-clock";
		#clock-cells = <0x00>;
		clock-frequency = <0x1fca034>;
		clock-output-names = "ref_clk";
		phandle = <0xa6>;
	};

	can0-clk {
		#clock-cells = <0x00>;
		compatible = "fixed-factor-clock";
		clocks = <0x82 0x60>;
		clock-div = <0x02>;
		clock-mult = <0x01>;
		clock-output-names = "can0_clk";
		phandle = <0xa0>;
	};

	can1-clk {
		#clock-cells = <0x00>;
		compatible = "fixed-factor-clock";
		clocks = <0x82 0x61>;
		clock-div = <0x02>;
		clock-mult = <0x01>;
		clock-output-names = "can1_clk";
		phandle = <0xa1>;
	};

	firmware {

		versal-firmware {
			compatible = "xlnx,versal-firmware";
			interrupt-parent = <0x4b>;
			bootph-all;
			method = "smc";
			#power-domain-cells = <0x01>;
			phandle = <0x81>;

			clock-controller {
				bootph-all;
				#clock-cells = <0x01>;
				compatible = "xlnx,versal-clk";
				clocks = <0xa6 0xa7>;
				clock-names = "ref\0pl_alt_ref";
				phandle = <0x82>;
			};

			power-management {
				compatible = "xlnx,zynqmp-power";
				phandle = <0x146>;
			};

			reset-controller {
				compatible = "xlnx,versal-reset";
				#reset-cells = <0x01>;
				phandle = <0xa3>;
			};

			pinctrl {
				compatible = "xlnx,versal-pinctrl";
				phandle = <0x147>;
			};

			versal-sec-cfg {
				compatible = "xlnx,versal-sec-cfg";
				#address-cells = <0x01>;
				#size-cells = <0x01>;
				phandle = <0x148>;

				nvmem-layout {
					compatible = "fixed-layout";
					#address-cells = <0x01>;
					#size-cells = <0x01>;

					bbram-zeroize@4 {
						reg = <0x04 0x04>;
						phandle = <0x149>;
					};

					bbram-key@10 {
						reg = <0x10 0x20>;
						phandle = <0x14a>;
					};

					bbram-usr@30 {
						reg = <0x30 0x04>;
						phandle = <0x14b>;
					};

					bbram-lock@48 {
						reg = <0x48 0x04>;
						phandle = <0x14c>;
					};

					user-key@110 {
						reg = <0x110 0x20>;
						phandle = <0x14d>;
					};

					user-key@130 {
						reg = <0x130 0x20>;
						phandle = <0x14e>;
					};

					user-key@150 {
						reg = <0x150 0x20>;
						phandle = <0x14f>;
					};

					user-key@170 {
						reg = <0x170 0x20>;
						phandle = <0x150>;
					};

					user-key@190 {
						reg = <0x190 0x20>;
						phandle = <0x151>;
					};

					user-key@1b0 {
						reg = <0x1b0 0x20>;
						phandle = <0x152>;
					};

					user-key@1d0 {
						reg = <0x1d0 0x20>;
						phandle = <0x153>;
					};

					user-key@1f0 {
						reg = <0x1f0 0x20>;
						phandle = <0x154>;
					};
				};
			};
		};
	};

	amba_pl {
		ranges;
		compatible = "simple-bus";
		#address-cells = <0x02>;
		#size-cells = <0x02>;
		firmware-name = "vpl_gen_fixed.pdi";
		phandle = <0x155>;

		misc_clk_1 {
			compatible = "fixed-clock";
			clock-frequency = <0x5f5e100>;
			#clock-cells = <0x00>;
			phandle = <0xaa>;
		};

		misc_clk_0 {
			compatible = "fixed-clock";
			clock-frequency = <0x5f5e09c>;
			#clock-cells = <0x00>;
			phandle = <0xa8>;
		};

		interrupt-controller@a4820000 {
			#interrupt-cells = <0x02>;
			interrupts = <0x00 0x54 0x04>;
			xlnx,sense-of-irq-edge-type = "Rising";
			xlnx,edk-special = "INTR_CTRL";
			xlnx,kind-of-intr = <0xffffffff>;
			xlnx,kind-of-edge = <0xffffffff>;
			xlnx,irq-is-level = <0x01>;
			xlnx,has-ivr = <0x01>;
			compatible = "xlnx,axi-intc-4.1\0xlnx,xps-intc-1.00.a";
			xlnx,disable-synchronizers = <0x00>;
			xlnx,kind-of-lvl = <0xffffffff>;
			xlnx,ivar-reset-value = <0x10>;
			xlnx,irq-active = <0x01>;
			interrupt-parent = <0x4b>;
			xlnx,en-cascade-mode = <0x00>;
			xlnx,ip-name = "axi_intc";
			xlnx,has-ilr = <0x00>;
			reg = <0x00 0xa4820000 0x00 0x10000>;
			xlnx,addr-width = <0x20>;
			clocks = <0xa8>;
			xlnx,s-axi-aclk-freq-mhz = <0x5f5e09c>;
			xlnx,num-sw-intr = <0x00>;
			xlnx,irq-connection = <0x01>;
			xlnx,num-intr-inputs = <0x20>;
			xlnx,has-sie = <0x01>;
			xlnx,enable-async = <0x00>;
			xlnx,has-cie = <0x01>;
			xlnx,num-sync-ff = <0x02>;
			xlnx,edk-iptype = "PERIPHERAL";
			xlnx,mb-clk-not-connected = <0x01>;
			xlnx,has-ipr = <0x01>;
			xlnx,sense-of-irq-level-type = "Active_High";
			xlnx,cascade-master = <0x00>;
			xlnx,processor-clk-freq-mhz = <0x64>;
			status = "okay";
			xlnx,is-fast = <0x00>;
			clock-names = "s_axi_aclk";
			xlnx,has-fast = <0x00>;
			xlnx,ivar-rst-val = <0x10>;
			interrupt-controller;
			interrupt-names = "irq";
			xlnx,async-intr = <0xffffffff>;
			phandle = <0x11>;
		};

		ai_engine@20000000000 {
			xlnx,num-mi-axi = <0x08>;
			compatible = "xlnx,ai-engine-2.0\0xlnx,ai-engine-v2.0";
			xlnx,aie-ref-clk-freqmhz = <0x1fc9f08>;
			xlnx,aie-col-dict = "col00 0x20000000000 col01 0x20002000000 col02 0x20004000000 col03 0x20006000000 col04 0x20008000000 col05 0x2000A000000 col06 0x2000C000000 col07 0x2000E000000 col08 0x20010000000 col09 0x20012000000 col10 0x20014000000 col11 0x20016000000 col12 0x20018000000 col13 0x2001A000000 col14 0x2001C000000 col15 0x2001E000000 col16 0x20020000000 col17 0x20022000000 col18 0x20024000000 col19 0x20026000000 col20 0x20028000000 col21 0x2002A000000 col22 0x2002C000000 col23 0x2002E000000 col24 0x20030000000 col25 0x20032000000 col26 0x20034000000 col27 0x20036000000 col28 0x20038000000 col29 0x2003A000000 col30 0x2003C000000 col31 0x2003E000000 col32 0x20040000000 col33 0x20042000000 col34 0x20044000000 col35 0x20046000000 col36 0x20048000000 col37 0x2004A000000";
			xlnx,num-mi-axis = <0x00>;
			xlnx,aie-max-freq = <0x4e2>;
			xlnx,en-addr-virtualization = <0x00>;
			xlnx,aie-gen = [02];
			xlnx,mem-rows = [01 02];
			xlnx,mi-destid-pins;
			xlnx,ip-name = "ai_engine";
			#size-cells = <0x02>;
			xlnx,num-si-axi = <0x01>;
			xlnx,fast-pm-write;
			reg = <0x200 0x00 0x01 0x00>;
			clocks = <0xa9>;
			xlnx,num-noc-axis-clks = <0x00>;
			ranges;
			xlnx,num-clks = <0x00>;
			xlnx,partition-enabled = <0x00>;
			#address-cells = <0x02>;
			xlnx,num-si-axis = <0x00>;
			xlnx,name-mi-axi = "M00_AXI";
			xlnx,num-column = <0x01>;
			xlnx,aie-core-ref-ctrl-freqmhz = <0x4e2>;
			xlnx,fast-dm-write;
			xlnx,edk-iptype = "PERIPHERAL";
			xlnx,selected-nsu = <0x00>;
			xlnx,available-nsu = "NOC_NSU128_X1Y6 0x20000000000 NOC_NSU128_X2Y6 0x20002000000 NOC_NSU128_X3Y6 0x20008000000 NOC_NSU128_X4Y6 0x2000A000000 NOC_NSU128_X5Y6 0x20018000000 NOC_NSU128_X6Y6 0x20020000000 NOC_NSU128_X7Y6 0x2002C000000 NOC_NSU128_X8Y6 0x20032000000 NOC_NSU128_X9Y6 0x2003E000000 NOC_NSU128_X10Y6 0x20042000000 NOC_NSU128_X11Y6 0x20046000000 NOC_NSU128_X12Y6 0x2004A000000";
			status = "okay";
			clock-names = "aclk0";
			power-domains = <0x81 0x18224072>;
			xlnx,num-trig-in = <0x00>;
			xlnx,nsu-dict = "NOC_NSU128_X1Y6 0x20000000000 NOC_NSU128_X2Y6 0x20002000000 NOC_NSU128_X3Y6 0x20008000000 NOC_NSU128_X4Y6 0x2000A000000 NOC_NSU128_X5Y6 0x20018000000 NOC_NSU128_X6Y6 0x20020000000 NOC_NSU128_X7Y6 0x2002C000000 NOC_NSU128_X8Y6 0x20032000000 NOC_NSU128_X9Y6 0x2003E000000 NOC_NSU128_X10Y6 0x20042000000 NOC_NSU128_X11Y6 0x20046000000 NOC_NSU128_X12Y6 0x2004A000000";
			xlnx,en-ext-rst = <0x01>;
			xlnx,num-trig-out = <0x00>;
			xlnx,core-rows = [03 08];
			xlnx,shim-rows = [00 01];
			xlnx,name-si-axi = "S00_AXI";
			xlnx,start-column = <0x00>;
			xlnx,aie-site = "AIE_ML";
			phandle = <0x7e>;

			aie_aperture@20000000000 {
				xlnx,device-name = <0x00>;
				interrupt-parent = <0x4b>;
				interrupts = <0x00 0x94 0x04 0x00 0x95 0x04 0x00 0x96 0x04>;
				#address-cells = <0x02>;
				power-domains = <0x81 0x18224072>;
				xlnx,node-id = <0x18800000>;
				#size-cells = <0x02>;
				interrupt-names = "interrupt1\0interrupt2\0interrupt3";
				reg = <0x200 0x00 0x01 0x00>;
				xlnx,columns = <0x00 0x26>;
				phandle = <0x156>;
			};
		};

		gpio@a4810000 {
			xlnx,gpio-board-interface = "Custom";
			compatible = "xlnx,axi-gpio-2.0\0xlnx,xps-gpio-1.00.a";
			xlnx,all-outputs = <0x01>;
			#gpio-cells = <0x02>;
			xlnx,gpio-width = <0x01>;
			xlnx,dout-default = <0x00>;
			xlnx,is-dual = <0x00>;
			xlnx,ip-name = "axi_gpio";
			xlnx,tri-default-2 = <0xffffffff>;
			reg = <0x00 0xa4810000 0x00 0x10000>;
			xlnx,all-inputs-2 = <0x00>;
			clocks = <0xaa>;
			xlnx,all-outputs-2 = <0x00>;
			gpio-controller;
			xlnx,interrupt-present = <0x00>;
			xlnx,gpio2-board-interface = "Custom";
			xlnx,edk-iptype = "PERIPHERAL";
			xlnx,dout-default-2 = <0x00>;
			status = "okay";
			xlnx,gpio2-width = <0x20>;
			clock-names = "s_axi_aclk";
			xlnx,tri-default = <0xffffffff>;
			xlnx,all-inputs = <0x00>;
			phandle = <0x10>;
		};

		axi_vip@a4800000 {
			xlnx,axi-has-cache = <0x01>;
			xlnx,has-user-bits-per-byte = <0x01>;
			xlnx,has-prot = <0x01>;
			xlnx,ip-name = "axi_vip";
			xlnx,has-aclken = <0x00>;
			reg = <0x00 0xa4800000 0x00 0x10000>;
			xlnx,axi-has-burst = <0x01>;
			xlnx,axi-rdata-width = <0x20>;
			xlnx,axi-has-lock = <0x01>;
			xlnx,has-wstrb = <0x01>;
			xlnx,has-qos = <0x01>;
			xlnx,has-size = <0x00>;
			xlnx,axi-buser-width = <0x00>;
			xlnx,aruser-width = <0x10>;
			xlnx,data-width = <0x20>;
			compatible = "xlnx,axi-vip-1.1";
			xlnx,axi-has-aresetn = <0x01>;
			xlnx,axi-has-wstrb = <0x01>;
			xlnx,axi-awuser-width = <0x10>;
			xlnx,axi-rid-width = <0x00>;
			xlnx,axi-has-prot = <0x01>;
			xlnx,has-bresp = <0x01>;
			xlnx,buser-width = <0x00>;
			xlnx,axi-wid-width = <0x00>;
			xlnx,axi-interface-mode = <0x02>;
			xlnx,has-aresetn = <0x01>;
			xlnx,axi-has-bresp = <0x01>;
			xlnx,axi-ruser-width = <0x00>;
			xlnx,axi-wdata-width = <0x20>;
			status = "okay";
			xlnx,axi-has-qos = <0x01>;
			xlnx,awuser-width = <0x10>;
			xlnx,ruser-bits-per-byte = <0x00>;
			xlnx,has-rresp = <0x01>;
			xlnx,supports-narrow = <0x00>;
			xlnx,slave-seg-type = "REG";
			xlnx,ruser-width = <0x00>;
			xlnx,read-write-mode = "READ_WRITE";
			xlnx,axi-addr-width = <0x20>;
			xlnx,addr-width = <0x20>;
			clocks = <0xa8>;
			xlnx,id-width = <0x00>;
			xlnx,axi-has-rresp = <0x01>;
			xlnx,edk-iptype = "PERIPHERAL";
			clock-names = "aclk";
			xlnx,protocol = "AXI4";
			xlnx,axi-wuser-width = <0x00>;
			xlnx,vip-pkg-name = <0x00>;
			xlnx,wuser-bits-per-byte = <0x00>;
			xlnx,has-lock = <0x01>;
			xlnx,wuser-width = <0x00>;
			xlnx,interface-mode = "SLAVE";
			xlnx,axi-has-region = <0x00>;
			xlnx,axi-supports-narrow = <0x00>;
			xlnx,has-cache = <0x01>;
			xlnx,has-region = <0x00>;
			xlnx,axi-aruser-width = <0x10>;
			xlnx,axi-protocol = <0x00>;
			xlnx,has-burst = <0x01>;
			phandle = <0x0f>;
		};

		vdu@a4000000 {
			reset-gpios = <0x10 0x00 0x01>;
			xlnx,mcu-clk = <0x23b>;
			xlnx,ip-name = "vdu";
			reg = <0x00 0xa4000000 0x00 0x800000>;
			xlnx,core-color-format-0 = <0x1a4>;
			xlnx,core-color-format-1 = <0x1a4>;
			xlnx,dec-frame-size-1 = <0x02>;
			xlnx,core-color-format-2 = <0x1a4>;
			xlnx,dec-frame-size-2 = <0x02>;
			xlnx,core-color-format-3 = <0x1a4>;
			xlnx,dec-video-standard-1 = <0x00>;
			xlnx,dec-frame-size-3 = <0x02>;
			xlnx,dec-video-standard-2 = <0x00>;
			xlnx,dec-frame-size-4 = <0x02>;
			xlnx,dec-video-standard-3 = <0x00>;
			xlnx,dec-video-standard-4 = <0x00>;
			compatible = "xlnx,vdu-2.0";
			xlnx,actual-mcu-clk = <0x23b>;
			xlnx,core-color-depth-0 = <0x0a>;
			xlnx,no-of-dec-instances = <0x01>;
			xlnx,lc-clkin-period = <0x0a>;
			xlnx,core-color-depth-1 = <0x0a>;
			xlnx,core-color-depth-2 = <0x0a>;
			xlnx,core-no-of-streams-0 = <0x01>;
			xlnx,core-color-depth-3 = <0x0a>;
			xlnx,core-no-of-streams-1 = <0x01>;
			xlnx,core-resolution-0 = "3840x2160";
			xlnx,dec-color-depth-1 = <0x01>;
			xlnx,core-no-of-streams-2 = <0x01>;
			xlnx,core-resolution-1 = "3840x2160";
			xlnx,dec-color-depth-2 = <0x01>;
			xlnx,core-no-of-streams-3 = <0x01>;
			xlnx,core-resolution-2 = "3840x2160";
			xlnx,core_clk = <0x320>;
			xlnx,no-of-dec-streams-1 = <0x01>;
			xlnx,dec-color-depth-3 = <0x01>;
			xlnx,core-resolution-3 = "3840x2160";
			xlnx,no-of-dec-streams-2 = <0x01>;
			xlnx,dec-color-depth-4 = <0x01>;
			xlnx,core-frame-per-second-0 = <0x3c>;
			xlnx,ref-clk = <0x64>;
			xlnx,no-of-dec-streams-3 = <0x01>;
			xlnx,core-frame-per-second-1 = <0x3c>;
			xlnx,no-of-dec-streams-4 = <0x01>;
			xlnx,core-frame-per-second-2 = <0x3c>;
			xlnx,core-frame-type-0 = "I_Frame";
			status = "okay";
			xlnx,core-frame-per-second-3 = <0x3c>;
			xlnx,core-frame-type-1 = "I_Frame";
			xlnx,core-frame-type-2 = "I_Frame";
			xlnx,core-frame-type-3 = "I_Frame";
			xlnx,clock-source = <0x01>;
			xlnx,enable-interrupt-combine;
			xlnx,dec-color-format-1 = <0x00>;
			xlnx,dec-color-format-2 = <0x00>;
			xlnx,mcu_clk = <0x23b>;
			xlnx,dec-color-format-3 = <0x00>;
			xlnx,dec-color-format-4 = <0x00>;
			xlnx,num-decoder-instances = <0x02>;
			clocks = <0xaa 0xaa 0x82 0x43 0xaa>;
			xlnx,enabledpll = <0x01>;
			xlnx,edk-iptype = "PERIPHERAL";
			xlnx,core-coding-standard-0 = "HEVC";
			xlnx,core-coding-standard-1 = "HEVC";
			clock-names = "m_axi_dec_aclk\0m_axi_mcu_aclk\0ref_clk\0s_axi_lite_aclk";
			xlnx,divclk-divide = <0x01>;
			xlnx,clkout3-divide = <0x07>;
			xlnx,core-coding-standard-2 = "HEVC";
			xlnx,dec-fps-1 = <0x03>;
			xlnx,core-coding-standard-3 = "HEVC";
			xlnx,dec-fps-2 = <0x03>;
			xlnx,clkin-period = <0x0a>;
			xlnx,clkfbout-mult = <0x28>;
			xlnx,dec-fps-3 = <0x03>;
			xlnx,dec-coding-type-1 = <0x00>;
			xlnx,lc-divclk-divide = <0x01>;
			xlnx,dec-fps-4 = <0x03>;
			xlnx,dec-coding-type-2 = <0x00>;
			xlnx,dec-coding-type-3 = <0x00>;
			xlnx,lc-clkfbout-mult = <0x28>;
			xlnx,dec-coding-type-4 = <0x00>;
			xlnx,clkout2-divide = <0x05>;
			xlnx,core-clk = <0x320>;
			xlnx,lc-clkout-divide2 = <0x05>;
			xlnx,lc-clkout-divide3 = <0x07>;
			xlnx,enable-test;
			xlnx,core-frequency-0 = <0x320>;
			xlnx,ref_clk = <0x64>;
			xlnx,core-frequency-1 = <0x320>;
			xlnx,actual-core-clk = <0x320>;
			xlnx,core-frequency-2 = <0x320>;
			xlnx,core-frequency-3 = <0x320>;
			phandle = <0x0e>;
		};

		aie_core_ref_clk_0 {
			compatible = "fixed-clock";
			clock-frequency = <0x4a817c80>;
			#clock-cells = <0x00>;
			phandle = <0xa9>;
		};

		al5d@a4020000 {
			interrupts = <0x00 0x55 0x04>;
			interrupt-parent = <0x4b>;
			status = "okay";
			compatible = "al,al5d";
			xlnx,vdu = <0x0e>;
			interrupt-names = "vdu_host_interrupt0";
			reg = <0x00 0xa4020000 0x00 0x100000>;
			al,devicename = "allegroDecodeIP0";
			phandle = <0x05>;
		};

		al5d@a4120000 {
			interrupts = <0x00 0x56 0x04>;
			interrupt-parent = <0x4b>;
			status = "okay";
			compatible = "al,al5d";
			xlnx,vdu = <0x0e>;
			interrupt-names = "vdu_host_interrupt1";
			reg = <0x00 0xa4120000 0x00 0x100000>;
			al,devicename = "allegroDecodeIP1";
			phandle = <0x06>;
		};

		zyxclmm_drm {
			compatible = "xlnx,zocl-versal";
		};
	};

	memory@00000000 {
		compatible = "xlnx,axi-noc-1.1";
		xlnx,ip-name = "axi_noc";
		device_type = "memory";
		reg = <0x00 0x00 0x00 0x80000000 0x08 0x80000000 0x00 0x80000000>;
		memory_type = "memory";
		phandle = <0x03>;
	};

	memory@50000000000 {
		compatible = "xlnx,axi-noc-1.1";
		xlnx,ip-name = "axi_noc";
		device_type = "memory";
		reg = <0x500 0x00 0x02 0x00>;
		memory_type = "memory";
		phandle = <0x04>;
	};

	chosen {
		stdout-path = "serial0:115200n8";
		bootargs = "console=ttyAMA0 earlycon=pl011,mmio32,0xFF000000,115200n8 root=/dev/ram0 rw init_fatal_sh=1 cma=1000M";
	};

	aliases {
		serial0 = "/axi/serial@ff000000";
		serial1 = "/axi/coresight@f0800000";
		i2c0 = "/axi/i2c@ff020000";
		i2c1 = "/axi/i2c@ff030000";
		ethernet0 = "/axi/ethernet@ff0c0000";
		serial2 = "/dcc";
		mmc0 = "/axi/mmc@f1050000";
		spi0 = "/axi/spi@f1010000";
		usb0 = "/axi/usb@ff9d0000";
		rtc0 = "/axi/rtc@f12a0000";
		nvmem0 = "/axi/i2c@ff030000/eeprom@54";
	};

	__symbols__ {
		cpus_a72 = "/cpus-a72@0";
		psv_cortexa72_0 = "/cpus-a72@0/cpu@0";
		psv_cortexa72_1 = "/cpus-a72@0/cpu@1";
		CPU_SLEEP_0 = "/cpus-a72@0/idle-states/cpu-sleep-0";
		cpu_opp_table = "/opp-table-cpu";
		dcc = "/dcc";
		fpga = "/fpga-region";
		psci = "/psci";
		timer = "/timer";
		versal_fpga = "/versal-fpga";
		sensor0 = "/versal-thermal-sensor";
		versal_thermal = "/thermal-zones/versal-thermal";
		temp_alert = "/thermal-zones/versal-thermal/trips/temp-alert";
		ot_crit = "/thermal-zones/versal-thermal/trips/ot-crit";
		amba_apu = "/apu-bus";
		gic_its = "/axi/interrupt-controller@f9000000/msi-controller@f9020000";
		amba = "/axi";
		imux = "/axi/interrupt-multiplex";
		can0 = "/axi/can@ff060000";
		can1 = "/axi/can@ff070000";
		cci = "/axi/cci@fd000000";
		cci_pmu = "/axi/cci@fd000000/pmu@10000";
		lpd_dma_chan0 = "/axi/dma-controller@ffa80000";
		lpd_dma_chan1 = "/axi/dma-controller@ffa90000";
		lpd_dma_chan2 = "/axi/dma-controller@ffaa0000";
		lpd_dma_chan3 = "/axi/dma-controller@ffab0000";
		lpd_dma_chan4 = "/axi/dma-controller@ffac0000";
		lpd_dma_chan5 = "/axi/dma-controller@ffad0000";
		lpd_dma_chan6 = "/axi/dma-controller@ffae0000";
		lpd_dma_chan7 = "/axi/dma-controller@ffaf0000";
		gem0 = "/axi/ethernet@ff0c0000";
		mdio = "/axi/ethernet@ff0c0000/mdio";
		phy0 = "/axi/ethernet@ff0c0000/mdio/ethernet-phy@1";
		gem1 = "/axi/ethernet@ff0d0000";
		gpio0 = "/axi/gpio@ff0b0000";
		gpio1 = "/axi/gpio@f1020000";
		i2c0 = "/axi/i2c@ff020000";
		i2c1 = "/axi/i2c@ff030000";
		eeprom = "/axi/i2c@ff030000/eeprom@54";
		i2c2 = "/axi/i2c@f1000000";
		mc0 = "/axi/memory-controller@f6150000";
		mc1 = "/axi/memory-controller@f62c0000";
		mc2 = "/axi/memory-controller@f6430000";
		mc3 = "/axi/memory-controller@f65a0000";
		ocm = "/axi/memory-controller@ff960000";
		rtc = "/axi/rtc@f12a0000";
		sdhci0 = "/axi/mmc@f1040000";
		sdhci1 = "/axi/mmc@f1050000";
		serial0 = "/axi/serial@ff000000";
		serial1 = "/axi/serial@ff010000";
		smmu = "/axi/iommu@fd800000";
		ospi = "/axi/spi@f1010000";
		qspi = "/axi/spi@f1030000";
		spi0 = "/axi/spi@ff040000";
		spi1 = "/axi/spi@ff050000";
		sysmon0 = "/axi/sysmon@f1270000";
		sysmon1 = "/axi/sysmon@109270000";
		sysmon2 = "/axi/sysmon@111270000";
		sysmon3 = "/axi/sysmon@119270000";
		usb0 = "/axi/usb@ff9d0000";
		dwc3_0 = "/axi/usb@ff9d0000/usb@fe200000";
		cpm_pciea = "/axi/pci@fca10000";
		pcie_intc_0 = "/axi/pci@fca10000/interrupt-controller";
		cpm5_pcie = "/axi/pcie@fcdd0000";
		pcie_intc_2 = "/axi/pcie@fcdd0000/interrupt-controller";
		watchdog = "/axi/watchdog@fd4d0000";
		watchdog1 = "/axi/watchdog@ff120000";
		xilsem_edac = "/axi/edac@f2014050";
		dma0 = "/axi/pmcdma@f11c0000";
		dma1 = "/axi/pmcdma@f11d0000";
		coresight = "/axi/coresight@f0800000";
		CIPS_0_pspmc_0_psv_coresight_fpd_cti1b = "/axi/CIPS_0_pspmc_0_psv_coresight_fpd_cti1b@f0bb0000";
		CIPS_0_pspmc_0_psv_coresight_fpd_cti1c = "/axi/CIPS_0_pspmc_0_psv_coresight_fpd_cti1c@f0bc0000";
		CIPS_0_pspmc_0_psv_coresight_fpd_cti1d = "/axi/CIPS_0_pspmc_0_psv_coresight_fpd_cti1d@f0bd0000";
		CIPS_0_pspmc_0_psv_coresight_lpd_cti = "/axi/CIPS_0_pspmc_0_psv_coresight_lpd_cti@f09d0000";
		CIPS_0_pspmc_0_psv_coresight_pmc_cti = "/axi/CIPS_0_pspmc_0_psv_coresight_pmc_cti@f08d0000";
		CIPS_0_pspmc_0_psv_coresight_r50_cti = "/axi/CIPS_0_pspmc_0_psv_coresight_r50_cti@f0a10000";
		CIPS_0_pspmc_0_psv_coresight_r51_cti = "/axi/CIPS_0_pspmc_0_psv_coresight_r51_cti@f0a50000";
		CIPS_0_pspmc_0_psv_cpm = "/axi/CIPS_0_pspmc_0_psv_cpm@0";
		amba_xppu = "/indirect-bus@1";
		lpd_xppu = "/indirect-bus@1/xppu@ff990000";
		pmc_xppu = "/indirect-bus@1/xppu@f1310000";
		pmc_xppu_npi = "/indirect-bus@1/xppu@f1300000";
		amba_xmpu = "/indirect-bus@2";
		fpd_xmpu = "/indirect-bus@2/xmpu@fd390000";
		pmc_xmpu = "/indirect-bus@2/xmpu@f12f0000";
		ocm_xmpu = "/indirect-bus@2/xmpu@ff980000";
		ddrmc_xmpu_0 = "/indirect-bus@2/xmpu@f6080000";
		ddrmc_xmpu_1 = "/indirect-bus@2/xmpu@f6220000";
		ddrmc_xmpu_2 = "/indirect-bus@2/xmpu@f6390000";
		ddrmc_xmpu_3 = "/indirect-bus@2/xmpu@f6500000";
		pl_alt_ref = "/pl-alt-ref";
		ref = "/ref";
		can0_clk = "/can0-clk";
		can1_clk = "/can1-clk";
		versal_firmware = "/firmware/versal-firmware";
		versal_clk = "/firmware/versal-firmware/clock-controller";
		zynqmp_power = "/firmware/versal-firmware/power-management";
		versal_reset = "/firmware/versal-firmware/reset-controller";
		pinctrl0 = "/firmware/versal-firmware/pinctrl";
		versal_sec_cfg = "/firmware/versal-firmware/versal-sec-cfg";
		bbram_zeroize = "/firmware/versal-firmware/versal-sec-cfg/nvmem-layout/bbram-zeroize@4";
		bbram_key = "/firmware/versal-firmware/versal-sec-cfg/nvmem-layout/bbram-key@10";
		bbram_usr = "/firmware/versal-firmware/versal-sec-cfg/nvmem-layout/bbram-usr@30";
		bbram_lock = "/firmware/versal-firmware/versal-sec-cfg/nvmem-layout/bbram-lock@48";
		user_key0 = "/firmware/versal-firmware/versal-sec-cfg/nvmem-layout/user-key@110";
		user_key1 = "/firmware/versal-firmware/versal-sec-cfg/nvmem-layout/user-key@130";
		user_key2 = "/firmware/versal-firmware/versal-sec-cfg/nvmem-layout/user-key@150";
		user_key3 = "/firmware/versal-firmware/versal-sec-cfg/nvmem-layout/user-key@170";
		user_key4 = "/firmware/versal-firmware/versal-sec-cfg/nvmem-layout/user-key@190";
		user_key5 = "/firmware/versal-firmware/versal-sec-cfg/nvmem-layout/user-key@1b0";
		user_key6 = "/firmware/versal-firmware/versal-sec-cfg/nvmem-layout/user-key@1d0";
		user_key7 = "/firmware/versal-firmware/versal-sec-cfg/nvmem-layout/user-key@1f0";
		amba_pl = "/amba_pl";
		misc_clk_1 = "/amba_pl/misc_clk_1";
		misc_clk_0 = "/amba_pl/misc_clk_0";
		axi_intc_parent = "/amba_pl/interrupt-controller@a4820000";
		ai_engine_0 = "/amba_pl/ai_engine@20000000000";
		aie_aperture_0 = "/amba_pl/ai_engine@20000000000/aie_aperture@20000000000";
		axi_gpio_0 = "/amba_pl/gpio@a4810000";
		dummy_slave_0 = "/amba_pl/axi_vip@a4800000";
		vdu_0 = "/amba_pl/vdu@a4000000";
		aie_core_ref_clk_0 = "/amba_pl/aie_core_ref_clk_0";
		al5d0 = "/amba_pl/al5d@a4020000";
		al5d1 = "/amba_pl/al5d@a4120000";
		noc_ddr4_ddr_memory = "/memory@00000000";
		noc_lpddr4_ddr_memory = "/memory@50000000000";
		gic = "/axi/interrupt-controller@f9000000";
		flash0 = "/axi/spi@f1010000/flash@0";
		pl_ddr = "/reserved-memory/buffer@0";
		lpddr_memory = "/reserved-memory/buffer@1";
	};

	domains {

		openamp_a72_0_cluster {
			compatible = "openamp,domain-v1";
			cpus = <0xab 0x01 0x80000003>;
			phandle = <0x161>;

			reserved-memory {
				ranges = <0x01>;

				rpu0vdev0vring1 {
					start = <0x9864000>;
					size = <0x4000>;
					no-map = <0x01>;
					phandle = <0x15c>;
				};

				rpu0vdev0vring0 {
					start = <0x9860000>;
					size = <0x4000>;
					no-map = <0x01>;
					phandle = <0x15b>;
				};

				rpu0vdev0buffer {
					start = <0x9868000>;
					size = <0x100000>;
					no-map = <0x01>;
					phandle = <0x15d>;
				};

				rproc0 {
					start = <0x9800000>;
					size = <0x60000>;
					no-map = <0x01>;
					phandle = <0x159>;
				};

				rpu1vdev0vring1 {
					start = <0x9e64000>;
					size = <0x4000>;
					no-map = <0x01>;
					phandle = <0x15f>;
				};

				rpu1vdev0vring0 {
					start = <0x9e60000>;
					size = <0x4000>;
					no-map = <0x01>;
					phandle = <0x15e>;
				};

				rpu1vdev0buffer {
					start = <0x9e68000>;
					size = <0x100000>;
					no-map = <0x01>;
					phandle = <0x160>;
				};

				rproc1 {
					start = <0x9e00000>;
					size = <0x60000>;
					no-map = <0x01>;
					phandle = <0x15a>;
				};
			};

			domain-to-domain {
				compatible = "openamp,domain-to-domain-v1";

				remoteproc-relation {
					compatible = "openamp,remoteproc-v2";
					remote = <0x157 0x158>;
					elfload;
					elfload0 = <0x7b 0x13f 0x159>;
					elfload1 = <0x7c 0x7d 0x15a>;
				};

				rpmsg-relation {
					compatible = "openamp,rpmsg-v1";
					openamp-xlnx-native = <0x00 0x00>;
					remote = <0x157 0x158>;
					mbox = <0x09 0x09>;
					carveouts = <0x15b 0x15c 0x15d 0x15e 0x15f 0x160>;
				};
			};

			access {
				dev = "psv_r5_0_btcm_global";
				flags = <0x00>;
			};
		};

		openamp_r5_0_cluster {
			compatible = "openamp,domain-v1";
			phandle = <0x157>;

			reserved-memory {
				ranges = <0x01>;

				rpu0vdev0vring1 {
					start = <0x9864000>;
					size = <0x4000>;
					no-map = <0x01>;
					phandle = <0x163>;
				};

				rpu0vdev0vring0 {
					start = <0x9860000>;
					size = <0x4000>;
					no-map = <0x01>;
					phandle = <0x162>;
				};

				rpu0vdev0buffer {
					start = <0x9868000>;
					size = <0x100000>;
					no-map = <0x01>;
					phandle = <0x164>;
				};

				rproc0 {
					start = <0x9800000>;
					size = <0x60000>;
					no-map = <0x01>;
				};
			};

			domain-to-domain {
				compatible = "openamp,domain-to-domain-v1";

				rpmsg-relation {
					compatible = "openamp,rpmsg-v1";
					host = <0x161>;
					mbox = <0x91>;
					carveouts = <0x162 0x163 0x164>;
				};
			};

			access {
				dev = "psv_r5_0_btcm_global";
				flags = <0x00>;
			};
		};

		openamp_r5_1_cluster {
			compatible = "openamp,domain-v1";
			phandle = <0x158>;

			reserved-memory {
				ranges = <0x01>;

				rpu1vdev0vring1 {
					start = <0x9e64000>;
					size = <0x4000>;
					no-map = <0x01>;
					phandle = <0x166>;
				};

				rpu1vdev0vring0 {
					start = <0x9e60000>;
					size = <0x4000>;
					no-map = <0x01>;
					phandle = <0x165>;
				};

				rpu1vdev0buffer {
					start = <0x9e68000>;
					size = <0x100000>;
					no-map = <0x01>;
					phandle = <0x167>;
				};

				rproc1 {
					start = <0x9e00000>;
					size = <0x60000>;
					no-map = <0x01>;
				};
			};

			domain-to-domain {
				compatible = "openamp,domain-to-domain-v1";

				rpmsg-relation {
					compatible = "openamp,rpmsg-v1";
					host = <0x161>;
					mbox = <0x9a>;
					carveouts = <0x165 0x166 0x167>;
				};
			};

			access {
				dev = "psv_r5_1_btcm_global";
				flags = <0x00>;
			};
		};
	};

	reserved-memory {
		#address-cells = <0x02>;
		#size-cells = <0x02>;
		ranges;

		rproc0 {
			no-map;
			reg = <0x00 0x9800000 0x00 0x60000>;
			phandle = <0x168>;
		};

		rproc1 {
			no-map;
			reg = <0x00 0x9e00000 0x00 0x60000>;
			phandle = <0x169>;
		};

		vdev0vring0@9860000 {
			no-map;
			reg = <0x00 0x9860000 0x00 0x4000>;
			phandle = <0x16a>;
		};

		vdev0vring1@9864000 {
			no-map;
			reg = <0x00 0x9864000 0x00 0x4000>;
			phandle = <0x16b>;
		};

		vdev0buffer@9868000 {
			no-map;
			reg = <0x00 0x9868000 0x00 0x100000>;
			compatible = "shared-dma-pool";
			phandle = <0x16c>;
		};

		vdev0vring0@9e60000 {
			no-map;
			reg = <0x00 0x9e60000 0x00 0x4000>;
			phandle = <0x16f>;
		};

		vdev0vring1@9e64000 {
			no-map;
			reg = <0x00 0x9e64000 0x00 0x4000>;
			phandle = <0x170>;
		};

		vdev0buffer@9e68000 {
			no-map;
			reg = <0x00 0x9e68000 0x00 0x100000>;
			compatible = "shared-dma-pool";
			phandle = <0x171>;
		};

		buffer@0 {
			no-map;
			reg = <0x08 0x00 0x00 0x80000000>;
			phandle = <0x08>;
		};

		buffer@1 {
			no-map;
			reg = <0x500 0x00 0x02 0x00>;
			phandle = <0x09>;
		};
	};

	remoteproc@ffe00000 {
		compatible = "xlnx,versal-r5fss";
		xlnx,cluster-mode = <0x00>;
		xlnx,tcm-mode = <0x00>;
		#address-cells = <0x02>;
		#size-cells = <0x02>;
		ranges = <0x00 0x00 0x00 0xffe00000 0x00 0x10000 0x00 0x20000 0x00 0xffe20000 0x00 0x10000 0x01 0x00 0x00 0xffe90000 0x00 0x10000 0x01 0x20000 0x00 0xffeb0000 0x00 0x10000>;

		r5f@0 {
			compatible = "xlnx,zynqmp-r5f";
			reg-names = "atcm0\0btcm0";
			reg = <0x00 0x00 0x00 0x10000 0x00 0x20000 0x00 0x10000>;
			memory-region = <0x168 0x16c 0x16a 0x16b>;
			power-domains = <0x81 0x18110005 0x81 0x1831800b 0x81 0x1831800c>;
			mboxes = <0x16e 0x00 0x16e 0x01>;
			mbox-names = "tx\0rx";
		};

		r5f@1 {
			compatible = "xlnx,zynqmp-r5f";
			reg-names = "atcm0\0btcm0";
			reg = <0x01 0x00 0x00 0x10000 0x01 0x20000 0x00 0x10000>;
			memory-region = <0x169 0x171 0x16f 0x170>;
			power-domains = <0x81 0x18110006 0x81 0x1831800d 0x81 0x1831800e>;
			mboxes = <0x172 0x00 0x172 0x01>;
			mbox-names = "tx\0rx";
		};
	};

	openamp_mailbox@ff360000 {
		#address-cells = <0x02>;
		#size-cells = <0x02>;
		compatible = "xlnx,versal-ipi-mailbox";
		reg = <0x00 0xff360000 0x00 0x20 0x00 0xff3f0a00 0x00 0x1ff>;
		xlnx,ipi-id = <0x05>;
		interrupts = <0x00 0x21 0x04>;
		reg-names = "ctrl\0msg";
		ranges;
		interrupt-parent = <0x4b>;
		phandle = <0x16d>;

		mailbox@ff340000 {
			phandle = <0x16e>;
			compatible = "xlnx,versal-ipi-dest-mailbox";
			#mbox-cells = <0x01>;
			reg-names = "ctrl\0msg";
			reg = <0x00 0xff340000 0x00 0x20 0x00 0xff3f0600 0x00 0x1ff>;
			xlnx,ipi-id = <0x03>;
		};

		mailbox@ff350000 {
			phandle = <0x172>;
			compatible = "xlnx,versal-ipi-dest-mailbox";
			#mbox-cells = <0x01>;
			reg-names = "ctrl\0msg";
			reg = <0x00 0xff350000 0x00 0x20 0x00 0xff3f0800 0x00 0x1ff>;
			xlnx,ipi-id = <0x04>;
		};
	};
};
